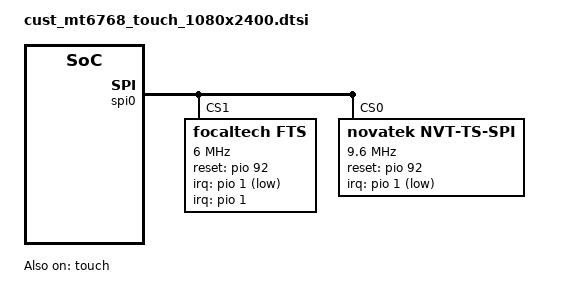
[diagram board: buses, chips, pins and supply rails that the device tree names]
/*
 * Copyright (c) 2019 MediaTek Inc.
 *
 * This program is free software; you can redistribute it and/or modify
 * it under the terms of the GNU General Public License version 2 as
 * published by the Free Software Foundation.
 *
 * This program is distributed in the hope that it will be useful,
 * but WITHOUT ANY WARRANTY; without even the implied warranty of
 * MERCHANTABILITY or FITNESS FOR A PARTICULAR PURPOSE.  See the
 * GNU General Public License for more details.
 */
/* TOUCH start */

&touch {
	tpd-resolution = <1080 2400>;
	use-tpd-button = <0>;
	tpd-key-num = <3>;
	tpd-key-local= <139 172 158 0>;
	tpd-key-dim-local = <90 883 100 40 230
				883 100 40 370 883 100 40 0 0 0 0>;
	tpd-max-touch-num = <10>;
	tpd-filter-enable = <0>;
	tpd-filter-pixel-density = <168>;
	tpd-filter-custom-prameters = <0 0 0 0 0 0 0 0 0 0 0 0>;
	tpd-filter-custom-speed = <0 0 0>;
	pinctrl-names = "default", "state_eint_as_int",
		"state_eint_output0", "state_eint_output1",
		"state_rst_output0", "state_rst_output1";
	pinctrl-0 = <&ctp_pins_default>;
	pinctrl-1 = <&ctp_pins_eint_as_int>;
	pinctrl-2 = <&ctp_pins_eint_output0>;
	pinctrl-3 = <&ctp_pins_eint_output1>;
	pinctrl-4 = <&ctp_pins_rst_output0>;
	pinctrl-5 = <&ctp_pins_rst_output1>;
	status = "okay";
};
&pio {
	ctp_pins_default: eint0default {
	};
	ctp_ts_pins_default: eint1default {
	};
	ctp_pins_eint_as_int: eint@0 {
		pins_cmd_dat {
			pinmux = <PINMUX_GPIO1__FUNC_GPIO1>;
			slew-rate = <0>;
			bias-disable;
		};
	};
	ctp_pins_eint_output0: eintoutput0 {
		pins_cmd_dat {
			pinmux = <PINMUX_GPIO1__FUNC_GPIO1>;
			slew-rate = <1>;
			output-low;
		};
	};
	ctp_pins_eint_output1: eintoutput1 {
		pins_cmd_dat {
			pinmux = <PINMUX_GPIO1__FUNC_GPIO1>;
			slew-rate = <1>;
			output-high;
	};
	};
	ctp_pins_rst_output0: rstoutput0 {
		pins_cmd_dat {
				pinmux = <PINMUX_GPIO92__FUNC_GPIO92>;
				slew-rate = <1>;
				output-low;
			};
	};
	ctp_pins_rst_output1: rstoutput1 {
		pins_cmd_dat {
				pinmux = <PINMUX_GPIO92__FUNC_GPIO92>;
				slew-rate = <1>;
				output-high;
		};
	};

};

&spi0 {
/*K19A coad for HQ-147450 by feiwen at 2021/7/23 start*/
	focaltech@0 {
		compatible = "focaltech,fts";
		reg = <1>;
		status = "ok";
		spi-max-frequency = <6000000>;
		interrupt-parent = <&pio>;
		interrupts = <1 0x2>;
		focaltech,reset-gpio = <&pio 92 0x00>;
		focaltech,irq-gpio = <&pio 1 0x2001>;
		focaltech,max-touch-number = <10>;
		focaltech,display-coords =  <0 0 1080 2400>;
	};
	novatek@0 {
		compatible = "novatek,NVT-ts-spi";
/*K19A coad for HQ-147450 by feiwen at 2021/7/23 end*/
		reg = <0>; //Same as CS ID
		status = "ok";

		spi-max-frequency = <9600000>;	//4800000,9600000,15000000,19200000
		novatek,reset-gpio = <&pio 92 0x00>;
		novatek,irq-gpio = <&pio 1 0x2001>;

		/* 525 */
		//novatek,swrst-n8-addr = <0x01F01A>;

		/* 672A, 525B, 675, 526, 672C */
		novatek,swrst-n8-addr = <0x03F0FE>;
		novatek,spi-rd-fast-addr = <0x03F310>;

		/* MP */
		novatek,mp-support-dt;

		/*for Xiaomi K19A 672C TM6.497" Module*/
		novatek-mp-criteria-5955@0 {
			#address-cells = <1>;
			#size-cells = <0>;
			compatible = "novatek-mp-criteria-5955";

			/* MP Config */
			IC_X_CFG_SIZE = <18>;
			IC_Y_CFG_SIZE = <36>;
			IC_KEY_CFG_SIZE = <4>;
			X_Channel = <18>;
			Y_Channel = <36>;
			AIN_X = <0 1 2 3 4 5 6 7 8 9 10 11 12 13 14 15 16 17>;
			AIN_Y = <0 1 2 3 4 5 6 7 8 9 10 11 12 13 14 15 16 17 18 19 20 21 22 23 24 25 26 27 28 29 30 31 32 33 34 35>;
			//AIN_X = <0 1 2 3 4 5 6 7 8 9 10 11 12 13 14 15 16 17 18 19 20 21 22 23 24 25 26 27 28 29 30 31>;
			//AIN_Y = <0 1 2 3 4 5 6 7 8 9 10 11 12 13 14 15 16 17 18 19 20 21 22 23 24 25 26 27 28 29 30 31 32 33 34 35 36 37 38 39 40 41 42 43 44 45 46 47 48 49>;
			AIN_KEY = <0 1 2 0xFF>;

			/* Huaqin modify for HQ-123586 by shujiawang at 2021/04/16 start */

			/* MP Criteria */
			PS_Config_Lmt_Short_Rawdata_P = <
				14008	14008	14008	14008	14008	14008	14008	14008	14008	14008	14008	14008	14008	14008	14008	14008	14008	14008
				14008	14008	14008	14008	14008	14008	14008	14008	14008	14008	14008	14008	14008	14008	14008	14008	14008	14008
				14008	14008	14008	14008	14008	14008	14008	14008	14008	14008	14008	14008	14008	14008	14008	14008	14008	14008
				14008	14008	14008	14008	14008	14008	14008	14008	14008	14008	14008	14008	14008	14008	14008	14008	14008	14008
				14008	14008	14008	14008	14008	14008	14008	14008	14008	14008	14008	14008	14008	14008	14008	14008	14008	14008
				14008	14008	14008	14008	14008	14008	14008	14008	14008	14008	14008	14008	14008	14008	14008	14008	14008	14008
				14008	14008	14008	14008	14008	14008	14008	14008	14008	14008	14008	14008	14008	14008	14008	14008	14008	14008
				14008	14008	14008	14008	14008	14008	14008	14008	14008	14008	14008	14008	14008	14008	14008	14008	14008	14008
				14008	14008	14008	14008	14008	14008	14008	14008	14008	14008	14008	14008	14008	14008	14008	14008	14008	14008
				14008	14008	14008	14008	14008	14008	14008	14008	14008	14008	14008	14008	14008	14008	14008	14008	14008	14008
				14008	14008	14008	14008	14008	14008	14008	14008	14008	14008	14008	14008	14008	14008	14008	14008	14008	14008
				14008	14008	14008	14008	14008	14008	14008	14008	14008	14008	14008	14008	14008	14008	14008	14008	14008	14008
				14008	14008	14008	14008	14008	14008	14008	14008	14008	14008	14008	14008	14008	14008	14008	14008	14008	14008
				14008	14008	14008	14008	14008	14008	14008	14008	14008	14008	14008	14008	14008	14008	14008	14008	14008	14008
				14008	14008	14008	14008	14008	14008	14008	14008	14008	14008	14008	14008	14008	14008	14008	14008	14008	14008
				14008	14008	14008	14008	14008	14008	14008	14008	14008	14008	14008	14008	14008	14008	14008	14008	14008	14008
				14008	14008	14008	14008	14008	14008	14008	14008	14008	14008	14008	14008	14008	14008	14008	14008	14008	14008
				14008	14008	14008	14008	14008	14008	14008	14008	14008	14008	14008	14008	14008	14008	14008	14008	14008	14008
				14008	14008	14008	14008	14008	14008	14008	14008	14008	14008	14008	14008	14008	14008	14008	14008	14008	14008
				14008	14008	14008	14008	14008	14008	14008	14008	14008	14008	14008	14008	14008	14008	14008	14008	14008	14008
				14008	14008	14008	14008	14008	14008	14008	14008	14008	14008	14008	14008	14008	14008	14008	14008	14008	14008
				14008	14008	14008	14008	14008	14008	14008	14008	14008	14008	14008	14008	14008	14008	14008	14008	14008	14008
				14008	14008	14008	14008	14008	14008	14008	14008	14008	14008	14008	14008	14008	14008	14008	14008	14008	14008
				14008	14008	14008	14008	14008	14008	14008	14008	14008	14008	14008	14008	14008	14008	14008	14008	14008	14008
				14008	14008	14008	14008	14008	14008	14008	14008	14008	14008	14008	14008	14008	14008	14008	14008	14008	14008
				14008	14008	14008	14008	14008	14008	14008	14008	14008	14008	14008	14008	14008	14008	14008	14008	14008	14008
				14008	14008	14008	14008	14008	14008	14008	14008	14008	14008	14008	14008	14008	14008	14008	14008	14008	14008
				14008	14008	14008	14008	14008	14008	14008	14008	14008	14008	14008	14008	14008	14008	14008	14008	14008	14008
				14008	14008	14008	14008	14008	14008	14008	14008	14008	14008	14008	14008	14008	14008	14008	14008	14008	14008
				14008	14008	14008	14008	14008	14008	14008	14008	14008	14008	14008	14008	14008	14008	14008	14008	14008	14008
				14008	14008	14008	14008	14008	14008	14008	14008	14008	14008	14008	14008	14008	14008	14008	14008	14008	14008
				14008	14008	14008	14008	14008	14008	14008	14008	14008	14008	14008	14008	14008	14008	14008	14008	14008	14008
				14008	14008	14008	14008	14008	14008	14008	14008	14008	14008	14008	14008	14008	14008	14008	14008	14008	14008
				14008	14008	14008	14008	14008	14008	14008	14008	14008	14008	14008	14008	14008	14008	14008	14008	14008	14008
				14008	14008	14008	14008	14008	14008	14008	14008	14008	14008	14008	14008	14008	14008	14008	14008	14008	14008
				14008	14008	14008	14008	14008	14008	14008	14008	14008	14008	14008	14008	14008	14008	14008	14008	14008	14008
				14008 14008 14008>;

			PS_Config_Lmt_Short_Rawdata_N = <
				10100	10100	10100	10100	10100	10100	10100	10100	10100	10100	10100	10100	10100	10100	10100	10100	10100	10100
				10100	10100	10100	10100	10100	10100	10100	10100	10100	10100	10100	10100	10100	10100	10100	10100	10100	10100
				10100	10100	10100	10100	10100	10100	10100	10100	10100	10100	10100	10100	10100	10100	10100	10100	10100	10100
				10100	10100	10100	10100	10100	10100	10100	10100	10100	10100	10100	10100	10100	10100	10100	10100	10100	10100
				10100	10100	10100	10100	10100	10100	10100	10100	10100	10100	10100	10100	10100	10100	10100	10100	10100	10100
				10100	10100	10100	10100	10100	10100	10100	10100	10100	10100	10100	10100	10100	10100	10100	10100	10100	10100
				10100	10100	10100	10100	10100	10100	10100	10100	10100	10100	10100	10100	10100	10100	10100	10100	10100	10100
				10100	10100	10100	10100	10100	10100	10100	10100	10100	10100	10100	10100	10100	10100	10100	10100	10100	10100
				10100	10100	10100	10100	10100	10100	10100	10100	10100	10100	10100	10100	10100	10100	10100	10100	10100	10100
				10100	10100	10100	10100	10100	10100	10100	10100	10100	10100	10100	10100	10100	10100	10100	10100	10100	10100
				10100	10100	10100	10100	10100	10100	10100	10100	10100	10100	10100	10100	10100	10100	10100	10100	10100	10100
				10100	10100	10100	10100	10100	10100	10100	10100	10100	10100	10100	10100	10100	10100	10100	10100	10100	10100
				10100	10100	10100	10100	10100	10100	10100	10100	10100	10100	10100	10100	10100	10100	10100	10100	10100	10100
				10100	10100	10100	10100	10100	10100	10100	10100	10100	10100	10100	10100	10100	10100	10100	10100	10100	10100
				10100	10100	10100	10100	10100	10100	10100	10100	10100	10100	10100	10100	10100	10100	10100	10100	10100	10100
				10100	10100	10100	10100	10100	10100	10100	10100	10100	10100	10100	10100	10100	10100	10100	10100	10100	10100
				10100	10100	10100	10100	10100	10100	10100	10100	10100	10100	10100	10100	10100	10100	10100	10100	10100	10100
				10100	10100	10100	10100	10100	10100	10100	10100	10100	10100	10100	10100	10100	10100	10100	10100	10100	10100
				10100	10100	10100	10100	10100	10100	10100	10100	10100	10100	10100	10100	10100	10100	10100	10100	10100	10100
				10100	10100	10100	10100	10100	10100	10100	10100	10100	10100	10100	10100	10100	10100	10100	10100	10100	10100
				10100	10100	10100	10100	10100	10100	10100	10100	10100	10100	10100	10100	10100	10100	10100	10100	10100	10100
				10100	10100	10100	10100	10100	10100	10100	10100	10100	10100	10100	10100	10100	10100	10100	10100	10100	10100
				10100	10100	10100	10100	10100	10100	10100	10100	10100	10100	10100	10100	10100	10100	10100	10100	10100	10100
				10100	10100	10100	10100	10100	10100	10100	10100	10100	10100	10100	10100	10100	10100	10100	10100	10100	10100
				10100	10100	10100	10100	10100	10100	10100	10100	10100	10100	10100	10100	10100	10100	10100	10100	10100	10100
				10100	10100	10100	10100	10100	10100	10100	10100	10100	10100	10100	10100	10100	10100	10100	10100	10100	10100
				10100	10100	10100	10100	10100	10100	10100	10100	10100	10100	10100	10100	10100	10100	10100	10100	10100	10100
				10100	10100	10100	10100	10100	10100	10100	10100	10100	10100	10100	10100	10100	10100	10100	10100	10100	10100
				10100	10100	10100	10100	10100	10100	10100	10100	10100	10100	10100	10100	10100	10100	10100	10100	10100	10100
				10100	10100	10100	10100	10100	10100	10100	10100	10100	10100	10100	10100	10100	10100	10100	10100	10100	10100
				10100	10100	10100	10100	10100	10100	10100	10100	10100	10100	10100	10100	10100	10100	10100	10100	10100	10100
				10100	10100	10100	10100	10100	10100	10100	10100	10100	10100	10100	10100	10100	10100	10100	10100	10100	10100
				10100	10100	10100	10100	10100	10100	10100	10100	10100	10100	10100	10100	10100	10100	10100	10100	10100	10100
				10100	10100	10100	10100	10100	10100	10100	10100	10100	10100	10100	10100	10100	10100	10100	10100	10100	10100
				10100	10100	10100	10100	10100	10100	10100	10100	10100	10100	10100	10100	10100	10100	10100	10100	10100	10100
				10100	10100	10100	10100	10100	10100	10100	10100	10100	10100	10100	10100	10100	10100	10100	10100	10100	10100
				10000 10000 10000>;

			PS_Config_Lmt_Open_Rawdata_P = <
				3207	3206	3302	3382	3417	3455	3509	3547	3544	3593	3595	3543	3455	3395	3336	3239	3105	3043
				3214	3250	3341	3438	3481	3523	3581	3631	3616	3655	3655	3598	3512	3449	3389	3285	3178	3133
				3267	3291	3374	3469	3511	3540	3593	3640	3638	3687	3707	3642	3554	3491	3431	3306	3197	3127
				3269	3309	3411	3519	3563	3593	3644	3689	3726	3750	3680	3628	3550	3491	3427	3294	3182	3151
				3320	3350	3442	3553	3600	3626	3668	3711	3806	3829	3749	3694	3606	3547	3469	3329	3196	3176
				3287	3336	3437	3556	3614	3654	3700	3753	3836	3829	3757	3708	3619	3564	3491	3353	3231	3243
				3378	3403	3498	3600	3654	3686	3731	3780	3885	3893	3819	3767	3689	3626	3546	3414	3267	3260
				3364	3407	3511	3613	3683	3726	3773	3803	3929	3897	3820	3768	3694	3637	3546	3413	3249	3305
				3448	3481	3572	3675	3743	3770	3810	3871	3980	3962	3893	3830	3752	3694	3598	3460	3346	3325
				3423	3472	3570	3679	3761	3798	3850	3920	4012	3967	3897	3843	3764	3712	3612	3477	3371	3386
				3483	3532	3620	3729	3802	3834	3833	3945	4044	4029	3955	3904	3819	3763	3638	3467	3390	3371
				3452	3515	3609	3724	3806	3847	3900	3974	4050	4002	3938	3893	3817	3774	3658	3537	3427	3445
				3533	3581	3675	3778	3868	3899	3950	4012	4102	4044	3984	3935	3862	3799	3680	3568	3455	3434
				3504	3570	3670	3773	3873	3911	3976	4039	4107	4076	4015	3967	3899	3841	3707	3603	3497	3514
				3574	3634	3721	3820	3913	3917	4011	4064	4145	4082	4020	3964	3886	3831	3672	3584	3480	3449
				3558	3638	3729	3830	3936	3988	4051	4116	4174	4103	4044	3987	3915	3859	3739	3621	3529	3536
				3586	3661	3735	3836	3939	4001	4061	4117	4184	4156	4086	4029	3946	3889	3768	3640	3533	3516
				3575	3666	3746	3855	3953	4039	4114	4176	4218	4142	4082	4026	3952	3882	3781	3659	3558	3582
				3684	3616	3647	3704	3724	3792	3861	3920	3981	3988	3956	3906	3829	3754	3735	3680	3628	3596
				3621	3585	3620	3690	3745	3805	3875	3941	4008	4019	3964	3906	3838	3785	3743	3690	3635	3620
				3687	3635	3665	3715	3763	3809	3873	3925	3984	4034	3988	3931	3876	3833	3792	3742	3682	3644
				3649	3623	3663	3693	3782	3836	3913	3964	4025	4022	3952	3899	3822	3815	3777	3725	3668	3651
				3722	3686	3719	3777	3831	3865	3934	3981	4043	4079	4023	3971	3922	3890	3841	3773	3703	3658
				3677	3668	3710	3788	3850	3900	3980	4033	4093	4057	3987	3931	3892	3861	3819	3756	3693	3668
				3715	3687	3733	3799	3854	3896	3960	4004	4057	4088	4030	3980	3939	3901	3857	3794	3719	3680
				3684	3690	3712	3802	3859	3908	3974	4029	4095	4124	4044	3963	3949	3914	3875	3810	3739	3715
				3756	3733	3791	3851	3908	3945	4011	4050	4109	4089	4023	3971	3936	3896	3859	3795	3731	3684
				3693	3698	3771	3836	3899	3941	4013	4057	4121	4145	4058	4013	3974	3939	3897	3834	3771	3743
				3749	3721	3806	3873	3922	3960	4025	4065	4132	4111	4026	4004	3960	3928	3883	3816	3745	3690
				3684	3705	3778	3854	3904	3950	4027	4069	4138	4118	4047	4009	3970	3943	3907	3845	3775	3749
				3746	3745	3822	3889	3934	3970	4033	4068	4125	4106	4050	4011	3971	3932	3892	3834	3752	3704
				3679	3707	3792	3857	3908	3964	4033	4081	4153	4142	4074	4039	4001	3971	3935	3871	3780	3763
				3728	3759	3841	3894	3939	3974	4034	4065	4128	4121	4085	4047	4011	3976	3942	3879	3788	3743
				3686	3833	3945	4012	4065	4113	4193	4240	4307	4249	4184	4144	4097	4060	4013	3939	3837	3712
				3536	3844	3948	4016	4071	4116	4187	4230	4300	4233	4174	4135	4074	4039	3990	3922	3802	3509
				3323	3760	3925	4008	4062	4107	4180	4233	4307	4260	4202	4174	4120	4089	4050	3978	3812	3421
				5120 5120 5120>;

			PS_Config_Lmt_Open_Rawdata_N = <
				1374	1374	1415	1449	1464	1480	1504	1520	1519	1540	1540	1518	1480	1455	1429	1388	1330	1304
				1377	1393	1432	1473	1492	1510	1534	1556	1549	1566	1566	1542	1505	1478	1452	1408	1362	1342
				1400	1410	1446	1486	1504	1517	1540	1560	1559	1580	1588	1561	1523	1496	1470	1417	1370	1340
				1401	1418	1462	1508	1527	1540	1561	1581	1597	1607	1577	1555	1521	1496	1468	1411	1363	1350
				1423	1435	1475	1522	1543	1554	1572	1590	1631	1641	1606	1583	1545	1520	1486	1426	1369	1361
				1408	1429	1473	1524	1549	1566	1585	1608	1644	1641	1610	1589	1551	1527	1496	1437	1384	1390
				1447	1458	1499	1543	1566	1579	1599	1620	1665	1668	1636	1614	1581	1554	1519	1463	1400	1397
				1441	1460	1504	1548	1578	1597	1617	1630	1684	1670	1637	1615	1583	1558	1519	1462	1392	1416
				1477	1492	1531	1575	1604	1615	1633	1659	1705	1698	1668	1641	1608	1583	1542	1483	1434	1425
				1467	1488	1530	1576	1612	1627	1650	1680	1719	1700	1670	1647	1613	1591	1548	1490	1444	1451
				1492	1513	1551	1598	1629	1643	1642	1690	1733	1726	1695	1673	1636	1612	1559	1486	1453	1444
				1479	1506	1546	1596	1631	1648	1671	1703	1735	1715	1687	1668	1636	1617	1567	1516	1468	1476
				1514	1534	1575	1619	1657	1671	1693	1719	1758	1733	1707	1686	1655	1628	1577	1529	1480	1471
				1501	1530	1573	1617	1660	1676	1704	1731	1760	1747	1720	1700	1671	1646	1588	1544	1498	1506
				1531	1557	1594	1637	1677	1678	1719	1741	1776	1749	1723	1699	1665	1642	1573	1536	1491	1478
				1525	1559	1598	1641	1687	1709	1736	1764	1789	1758	1733	1708	1678	1654	1602	1552	1512	1515
				1537	1569	1600	1644	1688	1714	1740	1764	1793	1781	1751	1726	1691	1666	1615	1560	1514	1507
				1532	1571	1605	1652	1694	1731	1763	1789	1807	1775	1749	1725	1693	1663	1620	1568	1525	1535
				1579	1549	1563	1587	1596	1625	1654	1680	1706	1709	1695	1674	1641	1609	1600	1577	1555	1541
				1552	1536	1551	1581	1605	1630	1660	1689	1717	1722	1699	1674	1645	1622	1604	1581	1558	1551
				1580	1558	1570	1592	1612	1632	1660	1682	1707	1729	1709	1684	1661	1642	1625	1603	1578	1561
				1564	1552	1570	1582	1621	1644	1677	1699	1725	1723	1693	1671	1638	1635	1618	1596	1572	1564
				1595	1579	1594	1618	1642	1656	1686	1706	1732	1748	1724	1702	1681	1667	1646	1617	1587	1567
				1576	1572	1590	1623	1650	1671	1705	1728	1754	1738	1708	1684	1668	1654	1636	1609	1582	1572
				1592	1580	1600	1628	1651	1669	1697	1716	1738	1752	1727	1705	1688	1672	1653	1626	1594	1577
				1579	1581	1591	1629	1654	1675	1703	1726	1755	1767	1733	1698	1692	1677	1660	1633	1602	1592
				1609	1600	1624	1650	1675	1690	1719	1735	1761	1752	1724	1702	1687	1669	1654	1626	1599	1579
				1582	1585	1616	1644	1671	1689	1720	1738	1766	1776	1739	1720	1703	1688	1670	1643	1616	1604
				1606	1594	1631	1660	1681	1697	1725	1742	1771	1762	1725	1716	1697	1683	1664	1635	1605	1581
				1579	1588	1619	1651	1673	1693	1726	1744	1773	1765	1734	1718	1701	1690	1674	1648	1618	1606
				1605	1605	1638	1666	1686	1701	1728	1743	1768	1759	1735	1719	1702	1685	1668	1643	1608	1587
				1576	1588	1625	1653	1675	1699	1728	1749	1780	1775	1746	1731	1714	1702	1686	1659	1620	1612
				1597	1611	1646	1669	1688	1703	1729	1742	1769	1766	1750	1734	1719	1704	1689	1662	1623	1604
				1579	1642	1690	1719	1742	1762	1797	1817	1846	1821	1793	1776	1756	1740	1720	1688	1644	1591
				1515	1647	1692	1721	1744	1764	1794	1813	1843	1814	1789	1772	1746	1731	1710	1681	1629	1504
				1424	1611	1682	1717	1741	1760	1791	1814	1846	1825	1801	1789	1765	1752	1735	1705	1633	1466
				(-511) (-511) (-511)>;

			PS_Config_Lmt_FW_Rawdata_P = <
				1129	1118	1120	1108	1108	1108	1108	1104	1122	1120	1114	1106	1110	1101	1111	1108	1122	1115
				1096	1121	1124	1097	1115	1097	1094	1117	1117	1129	1125	1113	1115	1114	1108	1108	1113	1125
				1111	1117	1117	1107	1122	1108	1108	1108	1129	1111	1115	1110	1104	1108	1113	1115	1118	1106
				1108	1110	1110	1115	1118	1118	1111	1107	1121	1118	1110	1113	1117	1115	1114	1110	1121	1117
				1104	1117	1110	1106	1111	1097	1099	1097	1107	1117	1120	1121	1121	1111	1118	1122	1120	1103
				1108	1125	1125	1108	1132	1097	1101	1100	1113	1125	1131	1125	1128	1134	1134	1131	1135	1096
				1108	1121	1121	1110	1120	1106	1108	1106	1113	1118	1113	1107	1113	1114	1113	1110	1101	1114
				1093	1132	1120	1113	1125	1096	1103	1108	1118	1121	1115	1115	1113	1106	1104	1113	1108	1114
				1114	1122	1111	1113	1117	1117	1115	1117	1117	1111	1107	1100	1104	1120	1113	1125	1117	1107
				1114	1121	1128	1121	1122	1107	1111	1110	1120	1120	1111	1114	1121	1115	1115	1122	1111	1106
				1100	1135	1132	1110	1122	1090	1093	1096	1099	1132	1128	1121	1100	1100	1100	1092	1090	1120
				1127	1106	1113	1118	1114	1132	1135	1114	1117	1113	1121	1121	1124	1120	1120	1120	1118	1101
				1113	1122	1122	1124	1125	1120	1117	1101	1124	1111	1113	1114	1114	1108	1111	1121	1120	1115
				1107	1125	1107	1096	1100	1097	1103	1129	1107	1122	1106	1108	1113	1117	1120	1118	1115	1106
				1108	1121	1122	1108	1121	1114	1114	1114	1124	1097	1106	1107	1124	1125	1127	1113	1117	1111
				1107	1125	1117	1113	1117	1103	1104	1122	1114	1121	1121	1122	1114	1117	1113	1113	1108	1110
				1113	1122	1128	1115	1120	1111	1108	1108	1115	1114	1110	1114	1113	1113	1104	1114	1115	1118
				1122	1108	1113	1117	1122	1122	1118	1120	1103	1125	1103	1115	1118	1104	1104	1103	1106	1113
				1113	1103	1107	1103	1103	1128	1120	1113	1122	1114	1118	1111	1107	1103	1101	1113	1127	1108
				1115	1113	1106	1104	1097	1115	1114	1106	1128	1114	1115	1107	1103	1111	1111	1120	1121	1107
				1115	1114	1113	1111	1113	1113	1115	1118	1120	1136	1111	1094	1092	1132	1103	1129	1132	1101
				1107	1108	1110	1115	1114	1115	1142	1138	1103	1113	1128	1100	1097	1108	1099	1106	1103	1118
				1117	1101	1087	1094	1092	1093	1111	1110	1121	1107	1115	1131	1129	1120	1121	1120	1104	1118
				1117	1124	1115	1114	1115	1113	1127	1122	1113	1114	1114	1111	1108	1120	1115	1115	1118	1121
				1118	1128	1127	1117	1127	1122	1127	1127	1125	1128	1121	1110	1111	1104	1097	1096	1110	1115
				1120	1104	1100	1104	1107	1103	1108	1110	1121	1129	1122	1093	1103	1101	1103	1101	1101	1114
				1118	1110	1111	1111	1111	1110	1121	1114	1124	1111	1121	1124	1122	1129	1132	1134	1129	1111
				1115	1111	1101	1103	1099	1101	1107	1114	1128	1129	1118	1101	1100	1103	1103	1100	1106	1121
				1103	1117	1121	1118	1120	1120	1118	1121	1115	1110	1127	1128	1124	1124	1125	1124	1124	1103
				1118	1103	1108	1104	1111	1108	1107	1108	1127	1114	1115	1125	1127	1125	1131	1127	1131	1110
				1117	1107	1117	1108	1120	1110	1115	1118	1118	1111	1120	1104	1121	1128	1125	1120	1121	1124
				1099	1122	1121	1124	1122	1111	1117	1117	1101	1120	1113	1125	1134	1124	1124	1124	1120	1113
				1120	1118	1111	1124	1114	1127	1108	1121	1120	1135	1132	1135	1127	1121	1124	1132	1110	1100
				1122	1120	1101	1108	1104	1110	1101	1110	1121	1115	1106	1120	1118	1124	1121	1129	1115	1108
				1121	1115	1117	1114	1121	1120	1125	1121	1110	1128	1118	1128	1117	1118	1115	1122	1114	1121
				1113	1121	1115	1114	1108	1111	1115	1122	1111	1103	1113	1127	1124	1127	1100	1114	1096	1092
				2560 2560 2560>;

			PS_Config_Lmt_FW_Rawdata_N = <
				484	479	480	475	475	475	475	473	481	480	477	474	475	472	476	475	481	478
				469	480	481	470	478	470	469	478	478	484	482	477	478	477	475	475	477	482
				476	478	478	474	481	475	475	475	484	476	478	475	473	475	477	478	479	474
				475	475	475	478	479	479	476	474	480	479	475	477	478	478	477	475	480	478
				473	478	475	474	476	470	471	470	474	478	480	480	480	476	479	481	480	472
				475	482	482	475	485	470	472	471	477	482	484	482	483	486	486	484	486	469
				475	480	480	475	480	474	475	474	477	479	477	474	477	477	477	475	472	477
				468	485	480	477	482	469	472	475	479	480	478	478	477	474	473	477	475	477
				477	481	476	477	478	478	478	478	478	476	474	471	473	480	477	482	478	474
				477	480	483	480	481	474	476	475	480	480	476	477	480	478	478	481	476	474
				471	486	485	475	481	467	468	469	471	485	483	480	471	471	471	468	467	480
				483	474	477	479	477	485	486	477	478	477	480	480	481	480	480	480	479	472
				477	481	481	481	482	480	478	472	481	476	477	477	477	475	476	480	480	478
				474	482	474	469	471	470	472	484	474	481	474	475	477	478	480	479	478	474
				475	480	481	475	480	477	477	477	481	470	474	474	481	482	483	477	478	476
				474	482	478	477	478	472	473	481	477	480	480	481	477	478	477	477	475	475
				477	481	483	478	480	476	475	475	478	477	475	477	477	477	473	477	478	479
				481	475	477	478	481	481	479	480	472	482	472	478	479	473	473	472	474	477
				477	472	474	472	472	483	480	477	481	477	479	476	474	472	472	477	483	475
				478	477	474	473	470	478	477	474	483	477	478	474	472	476	476	480	480	474
				478	477	477	476	477	477	478	479	480	487	476	469	468	485	472	484	485	472
				474	475	475	478	477	478	489	487	472	477	483	471	470	475	471	474	472	479
				478	472	466	469	468	468	476	475	480	474	478	484	484	480	480	480	473	479
				478	481	478	477	478	477	483	481	477	477	477	476	475	480	478	478	479	480
				479	483	483	478	483	481	483	483	482	483	480	475	476	473	470	469	475	478
				480	473	471	473	474	472	475	475	480	484	481	468	472	472	472	472	472	477
				479	475	476	476	476	475	480	477	481	476	480	481	481	484	485	486	484	476
				478	476	472	472	471	472	474	477	483	484	479	472	471	472	472	471	474	480
				472	478	480	479	480	480	479	480	478	475	483	483	481	481	482	481	481	472
				479	472	475	473	476	475	474	475	483	477	478	482	483	482	484	483	484	475
				478	474	478	475	480	475	478	479	479	476	480	473	480	483	482	480	480	481
				471	481	480	481	481	476	478	478	472	480	477	482	486	481	481	481	480	477
				480	479	476	481	477	483	475	480	480	486	485	486	483	480	481	485	475	471
				481	480	472	475	473	475	472	475	480	478	474	480	479	481	480	484	478	475
				480	478	478	477	480	480	482	480	475	483	479	483	478	479	478	481	477	480
				477	480	478	477	475	476	478	481	476	472	477	483	481	483	471	477	469	468
				240 240 240>;

			PS_Config_Lmt_FW_CC_P = <
				52	52	52	53	52	53	53	53	55	55	53	53	53	52	52	52	52	52
				52	52	52	52	52	52	52	53	55	53	52	52	52	52	52	52	52	52
				52	52	52	52	52	52	52	52	55	53	52	52	52	52	52	52	52	52
				53	52	52	52	52	52	52	53	55	53	52	52	52	52	52	52	52	53
				52	52	52	52	52	52	52	52	53	53	52	52	52	52	52	52	52	52
				53	52	52	52	52	53	53	53	55	53	52	52	52	52	52	52	52	53
				52	52	52	52	52	52	52	52	53	53	52	52	52	52	52	52	52	52
				53	52	52	52	52	53	53	53	55	55	53	53	52	52	52	52	52	53
				52	52	52	52	52	52	52	52	53	55	53	53	52	52	52	52	52	53
				53	52	52	52	52	53	53	53	55	55	53	52	52	52	52	52	52	53
				52	52	52	52	52	52	52	53	55	55	53	53	52	52	53	52	52	53
				53	52	52	53	53	53	53	53	55	55	53	53	52	52	52	52	52	53
				52	52	52	52	52	52	52	53	55	53	53	53	52	52	52	52	52	53
				53	52	52	53	52	53	53	53	55	53	53	53	52	52	52	52	52	53
				52	52	52	52	52	52	53	53	55	53	53	53	52	52	52	52	52	53
				53	52	52	53	52	53	53	53	56	53	52	52	52	52	52	52	52	53
				52	52	52	52	52	52	53	53	55	53	53	53	53	52	52	52	52	53
				53	52	52	52	52	53	53	53	56	53	52	52	52	52	52	52	52	53
				53	52	52	52	52	52	52	52	52	56	53	53	52	52	52	52	52	53
				53	52	52	52	52	53	53	53	53	56	53	53	53	52	52	52	52	53
				52	52	52	52	52	52	52	52	52	55	53	53	53	52	52	52	52	53
				53	52	52	52	52	52	53	53	53	55	53	53	53	52	52	52	52	53
				53	52	52	52	52	52	52	52	53	55	53	53	53	52	52	52	52	53
				53	52	52	52	52	52	53	53	53	55	53	52	53	52	52	52	52	53
				53	52	52	52	52	52	52	52	53	55	53	53	53	52	53	52	52	53
				53	53	53	53	53	53	53	53	55	55	53	53	53	52	52	52	52	53
				53	52	52	52	52	52	52	52	55	55	52	52	52	52	52	52	52	53
				53	52	53	53	53	53	53	53	55	55	53	53	53	53	53	53	52	53
				53	52	52	52	52	52	52	52	53	55	53	53	53	52	52	52	52	53
				53	52	52	52	52	52	53	53	55	55	53	52	52	52	52	52	52	53
				53	52	52	52	52	52	52	52	53	55	52	53	52	52	52	52	52	53
				53	52	53	52	53	52	53	52	55	55	53	53	53	52	53	53	52	53
				53	52	52	52	53	52	52	52	55	55	52	52	52	52	52	52	52	53
				53	53	53	53	53	53	53	53	56	55	53	52	52	52	52	52	52	53
				52	52	52	52	52	52	52	52	55	55	52	52	52	52	52	52	52	52
				52	52	53	53	53	53	53	53	56	55	53	53	52	52	52	52	52	52
				314 314 314>;

			PS_Config_Lmt_FW_CC_N = <
				23	23	23	24	23	24	24	24	24	24	24	24	24	23	23	23	23	23
				23	23	23	23	23	23	23	24	24	24	23	23	23	23	23	23	23	23
				23	23	23	23	23	23	23	23	24	24	23	23	23	23	23	23	23	23
				24	23	23	23	23	23	23	24	24	24	23	23	23	23	23	23	23	24
				23	23	23	23	23	23	23	23	24	24	23	23	23	23	23	23	23	23
				24	23	23	23	23	24	24	24	24	24	23	23	23	23	23	23	23	24
				23	23	23	23	23	23	23	23	24	24	23	23	23	23	23	23	23	23
				24	23	23	23	23	24	24	24	24	24	24	24	23	23	23	23	23	24
				23	23	23	23	23	23	23	23	24	24	24	24	23	23	23	23	23	24
				24	23	23	23	23	24	24	24	24	24	24	23	23	23	23	23	23	24
				23	23	23	23	23	23	23	24	24	24	24	24	23	23	24	23	23	24
				24	23	23	24	24	24	24	24	24	24	24	24	23	23	23	23	23	24
				23	23	23	23	23	23	23	24	24	24	24	24	23	23	23	23	23	24
				24	23	23	24	23	24	24	24	24	24	24	24	23	23	23	23	23	24
				23	23	23	23	23	23	24	24	24	24	24	24	23	23	23	23	23	24
				24	23	23	24	23	24	24	24	25	24	23	23	23	23	23	23	23	24
				23	23	23	23	23	23	24	24	24	24	24	24	24	23	23	23	23	24
				24	23	23	23	23	24	24	24	25	24	23	23	23	23	23	23	23	24
				24	23	23	23	23	23	23	23	23	25	24	24	23	23	23	23	23	24
				24	23	23	23	23	24	24	24	24	25	24	24	24	23	23	23	23	24
				23	23	23	23	23	23	23	23	23	24	24	24	24	23	23	23	23	24
				24	23	23	23	23	23	24	24	24	24	24	24	24	23	23	23	23	24
				24	23	23	23	23	23	23	23	24	24	24	24	24	23	23	23	23	24
				24	23	23	23	23	23	24	24	24	24	24	23	24	23	23	23	23	24
				24	23	23	23	23	23	23	23	24	24	24	24	24	23	24	23	23	24
				24	24	24	24	24	24	24	24	24	24	24	24	24	23	23	23	23	24
				24	23	23	23	23	23	23	23	24	24	23	23	23	23	23	23	23	24
				24	23	24	24	24	24	24	24	24	24	24	24	24	24	24	24	23	24
				24	23	23	23	23	23	23	23	24	24	24	24	24	23	23	23	23	24
				24	23	23	23	23	23	24	24	24	24	24	23	23	23	23	23	23	24
				24	23	23	23	23	23	23	23	24	24	23	24	23	23	23	23	23	24
				24	23	24	23	24	23	24	23	24	24	24	24	24	23	24	24	23	24
				24	23	23	23	24	23	23	23	24	24	23	23	23	23	23	23	23	24
				24	24	24	24	24	24	24	24	25	24	24	23	23	23	23	23	23	24
				23	23	23	23	23	23	23	23	24	24	23	23	23	23	23	23	23	23
				23	23	24	24	24	24	24	24	25	24	24	24	23	23	23	23	23	23
				0 0 0>;

			PS_Config_Lmt_FW_Diff_P = <
				50	50	50	50	50	50	50	50	50	50	50	50	50	50	50	50	50	50
				50	50	50	50	50	50	50	50	50	50	50	50	50	50	50	50	50	50
				50	50	50	50	50	50	50	50	50	50	50	50	50	50	50	50	50	50
				50	50	50	50	50	50	50	50	50	50	50	50	50	50	50	50	50	50
				50	50	50	50	50	50	50	50	50	50	50	50	50	50	50	50	50	50
				50	50	50	50	50	50	50	50	50	50	50	50	50	50	50	50	50	50
				50	50	50	50	50	50	50	50	50	50	50	50	50	50	50	50	50	50
				50	50	50	50	50	50	50	50	50	50	50	50	50	50	50	50	50	50
				50	50	50	50	50	50	50	50	50	50	50	50	50	50	50	50	50	50
				50	50	50	50	50	50	50	50	50	50	50	50	50	50	50	50	50	50
				50	50	50	50	50	50	50	50	50	50	50	50	50	50	50	50	50	50
				50	50	50	50	50	50	50	50	50	50	50	50	50	50	50	50	50	50
				50	50	50	50	50	50	50	50	50	50	50	50	50	50	50	50	50	50
				50	50	50	50	50	50	50	50	50	50	50	50	50	50	50	50	50	50
				50	50	50	50	50	50	50	50	50	50	50	50	50	50	50	50	50	50
				50	50	50	50	50	50	50	50	50	50	50	50	50	50	50	50	50	50
				50	50	50	50	50	50	50	50	50	50	50	50	50	50	50	50	50	50
				50	50	50	50	50	50	50	50	50	50	50	50	50	50	50	50	50	50
				50	50	50	50	50	50	50	50	50	50	50	50	50	50	50	50	50	50
				50	50	50	50	50	50	50	50	50	50	50	50	50	50	50	50	50	50
				50	50	50	50	50	50	50	50	50	50	50	50	50	50	50	50	50	50
				50	50	50	50	50	50	50	50	50	50	50	50	50	50	50	50	50	50
				50	50	50	50	50	50	50	50	50	50	50	50	50	50	50	50	50	50
				50	50	50	50	50	50	50	50	50	50	50	50	50	50	50	50	50	50
				50	50	50	50	50	50	50	50	50	50	50	50	50	50	50	50	50	50
				50	50	50	50	50	50	50	50	50	50	50	50	50	50	50	50	50	50
				50	50	50	50	50	50	50	50	50	50	50	50	50	50	50	50	50	50
				50	50	50	50	50	50	50	50	50	50	50	50	50	50	50	50	50	50
				50	50	50	50	50	50	50	50	50	50	50	50	50	50	50	50	50	50
				50	50	50	50	50	50	50	50	50	50	50	50	50	50	50	50	50	50
				50	50	50	50	50	50	50	50	50	50	50	50	50	50	50	50	50	50
				50	50	50	50	50	50	50	50	50	50	50	50	50	50	50	50	50	50
				50	50	50	50	50	50	50	50	50	50	50	50	50	50	50	50	50	50
				50	50	50	50	50	50	50	50	50	50	50	50	50	50	50	50	50	50
				50	50	50	50	50	50	50	50	50	50	50	50	50	50	50	50	50	50
				50	50	50	50	50	50	50	50	50	50	50	50	50	50	50	50	50	50
				75 75 75>;

			PS_Config_Lmt_FW_Diff_N = <
				(-50)	(-50)	(-50)	(-50)	(-50)	(-50)	(-50)	(-50)	(-50)	(-50)	(-50)	(-50)	(-50)	(-50)	(-50)	(-50)	(-50)	(-50)
				(-50)	(-50)	(-50)	(-50)	(-50)	(-50)	(-50)	(-50)	(-50)	(-50)	(-50)	(-50)	(-50)	(-50)	(-50)	(-50)	(-50)	(-50)
				(-50)	(-50)	(-50)	(-50)	(-50)	(-50)	(-50)	(-50)	(-50)	(-50)	(-50)	(-50)	(-50)	(-50)	(-50)	(-50)	(-50)	(-50)
				(-50)	(-50)	(-50)	(-50)	(-50)	(-50)	(-50)	(-50)	(-50)	(-50)	(-50)	(-50)	(-50)	(-50)	(-50)	(-50)	(-50)	(-50)
				(-50)	(-50)	(-50)	(-50)	(-50)	(-50)	(-50)	(-50)	(-50)	(-50)	(-50)	(-50)	(-50)	(-50)	(-50)	(-50)	(-50)	(-50)
				(-50)	(-50)	(-50)	(-50)	(-50)	(-50)	(-50)	(-50)	(-50)	(-50)	(-50)	(-50)	(-50)	(-50)	(-50)	(-50)	(-50)	(-50)
				(-50)	(-50)	(-50)	(-50)	(-50)	(-50)	(-50)	(-50)	(-50)	(-50)	(-50)	(-50)	(-50)	(-50)	(-50)	(-50)	(-50)	(-50)
				(-50)	(-50)	(-50)	(-50)	(-50)	(-50)	(-50)	(-50)	(-50)	(-50)	(-50)	(-50)	(-50)	(-50)	(-50)	(-50)	(-50)	(-50)
				(-50)	(-50)	(-50)	(-50)	(-50)	(-50)	(-50)	(-50)	(-50)	(-50)	(-50)	(-50)	(-50)	(-50)	(-50)	(-50)	(-50)	(-50)
				(-50)	(-50)	(-50)	(-50)	(-50)	(-50)	(-50)	(-50)	(-50)	(-50)	(-50)	(-50)	(-50)	(-50)	(-50)	(-50)	(-50)	(-50)
				(-50)	(-50)	(-50)	(-50)	(-50)	(-50)	(-50)	(-50)	(-50)	(-50)	(-50)	(-50)	(-50)	(-50)	(-50)	(-50)	(-50)	(-50)
				(-50)	(-50)	(-50)	(-50)	(-50)	(-50)	(-50)	(-50)	(-50)	(-50)	(-50)	(-50)	(-50)	(-50)	(-50)	(-50)	(-50)	(-50)
				(-50)	(-50)	(-50)	(-50)	(-50)	(-50)	(-50)	(-50)	(-50)	(-50)	(-50)	(-50)	(-50)	(-50)	(-50)	(-50)	(-50)	(-50)
				(-50)	(-50)	(-50)	(-50)	(-50)	(-50)	(-50)	(-50)	(-50)	(-50)	(-50)	(-50)	(-50)	(-50)	(-50)	(-50)	(-50)	(-50)
				(-50)	(-50)	(-50)	(-50)	(-50)	(-50)	(-50)	(-50)	(-50)	(-50)	(-50)	(-50)	(-50)	(-50)	(-50)	(-50)	(-50)	(-50)
				(-50)	(-50)	(-50)	(-50)	(-50)	(-50)	(-50)	(-50)	(-50)	(-50)	(-50)	(-50)	(-50)	(-50)	(-50)	(-50)	(-50)	(-50)
				(-50)	(-50)	(-50)	(-50)	(-50)	(-50)	(-50)	(-50)	(-50)	(-50)	(-50)	(-50)	(-50)	(-50)	(-50)	(-50)	(-50)	(-50)
				(-50)	(-50)	(-50)	(-50)	(-50)	(-50)	(-50)	(-50)	(-50)	(-50)	(-50)	(-50)	(-50)	(-50)	(-50)	(-50)	(-50)	(-50)
				(-50)	(-50)	(-50)	(-50)	(-50)	(-50)	(-50)	(-50)	(-50)	(-50)	(-50)	(-50)	(-50)	(-50)	(-50)	(-50)	(-50)	(-50)
				(-50)	(-50)	(-50)	(-50)	(-50)	(-50)	(-50)	(-50)	(-50)	(-50)	(-50)	(-50)	(-50)	(-50)	(-50)	(-50)	(-50)	(-50)
				(-50)	(-50)	(-50)	(-50)	(-50)	(-50)	(-50)	(-50)	(-50)	(-50)	(-50)	(-50)	(-50)	(-50)	(-50)	(-50)	(-50)	(-50)
				(-50)	(-50)	(-50)	(-50)	(-50)	(-50)	(-50)	(-50)	(-50)	(-50)	(-50)	(-50)	(-50)	(-50)	(-50)	(-50)	(-50)	(-50)
				(-50)	(-50)	(-50)	(-50)	(-50)	(-50)	(-50)	(-50)	(-50)	(-50)	(-50)	(-50)	(-50)	(-50)	(-50)	(-50)	(-50)	(-50)
				(-50)	(-50)	(-50)	(-50)	(-50)	(-50)	(-50)	(-50)	(-50)	(-50)	(-50)	(-50)	(-50)	(-50)	(-50)	(-50)	(-50)	(-50)
				(-50)	(-50)	(-50)	(-50)	(-50)	(-50)	(-50)	(-50)	(-50)	(-50)	(-50)	(-50)	(-50)	(-50)	(-50)	(-50)	(-50)	(-50)
				(-50)	(-50)	(-50)	(-50)	(-50)	(-50)	(-50)	(-50)	(-50)	(-50)	(-50)	(-50)	(-50)	(-50)	(-50)	(-50)	(-50)	(-50)
				(-50)	(-50)	(-50)	(-50)	(-50)	(-50)	(-50)	(-50)	(-50)	(-50)	(-50)	(-50)	(-50)	(-50)	(-50)	(-50)	(-50)	(-50)
				(-50)	(-50)	(-50)	(-50)	(-50)	(-50)	(-50)	(-50)	(-50)	(-50)	(-50)	(-50)	(-50)	(-50)	(-50)	(-50)	(-50)	(-50)
				(-50)	(-50)	(-50)	(-50)	(-50)	(-50)	(-50)	(-50)	(-50)	(-50)	(-50)	(-50)	(-50)	(-50)	(-50)	(-50)	(-50)	(-50)
				(-50)	(-50)	(-50)	(-50)	(-50)	(-50)	(-50)	(-50)	(-50)	(-50)	(-50)	(-50)	(-50)	(-50)	(-50)	(-50)	(-50)	(-50)
				(-50)	(-50)	(-50)	(-50)	(-50)	(-50)	(-50)	(-50)	(-50)	(-50)	(-50)	(-50)	(-50)	(-50)	(-50)	(-50)	(-50)	(-50)
				(-50)	(-50)	(-50)	(-50)	(-50)	(-50)	(-50)	(-50)	(-50)	(-50)	(-50)	(-50)	(-50)	(-50)	(-50)	(-50)	(-50)	(-50)
				(-50)	(-50)	(-50)	(-50)	(-50)	(-50)	(-50)	(-50)	(-50)	(-50)	(-50)	(-50)	(-50)	(-50)	(-50)	(-50)	(-50)	(-50)
				(-50)	(-50)	(-50)	(-50)	(-50)	(-50)	(-50)	(-50)	(-50)	(-50)	(-50)	(-50)	(-50)	(-50)	(-50)	(-50)	(-50)	(-50)
				(-50)	(-50)	(-50)	(-50)	(-50)	(-50)	(-50)	(-50)	(-50)	(-50)	(-50)	(-50)	(-50)	(-50)	(-50)	(-50)	(-50)	(-50)
				(-50)	(-50)	(-50)	(-50)	(-50)	(-50)	(-50)	(-50)	(-50)	(-50)	(-50)	(-50)	(-50)	(-50)	(-50)	(-50)	(-50)	(-50)
				(-75) (-75) (-75)>;

			PS_Config_Lmt_PenTipX_FW_Raw_P = <
				570 570 570 570 570 570 570 570 570 570 570 570 570 570 570 570 570 570 570 570 570 570 570 570 570 570 570 570 570 570 570 570
				570 570 570 570 570 570 570 570 570 570 570 570 570 570 570 570 570 570 570 570 570 570 570 570 570 570 570 570 570 570 570 570
				570 570 570 570 570 570 570 570 570 570 570 570 570 570 570 570 570 570 570 570 570 570 570 570 570 570 570 570 570 570 570 570
				570 570 570 570 570 570 570 570 570 570 570 570 570 570 570 570 570 570 570 570 570 570 570 570 570 570 570 570 570 570 570 570
				570 570 570 570 570 570 570 570 570 570 570 570 570 570 570 570 570 570 570 570 570 570 570 570 570 570 570 570 570 570 570 570
				570 570 570 570 570 570 570 570 570 570 570 570 570 570 570 570 570 570 570 570 570 570 570 570 570 570 570 570 570 570 570 570>;

			PS_Config_Lmt_PenTipX_FW_Raw_N = <
				(-570) (-570) (-570) (-570) (-570) (-570) (-570) (-570) (-570) (-570) (-570) (-570) (-570) (-570) (-570) (-570) (-570) (-570) (-570) (-570) (-570) (-570) (-570) (-570) (-570) (-570) (-570) (-570) (-570) (-570) (-570) (-570)
				(-570) (-570) (-570) (-570) (-570) (-570) (-570) (-570) (-570) (-570) (-570) (-570) (-570) (-570) (-570) (-570) (-570) (-570) (-570) (-570) (-570) (-570) (-570) (-570) (-570) (-570) (-570) (-570) (-570) (-570) (-570) (-570)
				(-570) (-570) (-570) (-570) (-570) (-570) (-570) (-570) (-570) (-570) (-570) (-570) (-570) (-570) (-570) (-570) (-570) (-570) (-570) (-570) (-570) (-570) (-570) (-570) (-570) (-570) (-570) (-570) (-570) (-570) (-570) (-570)
				(-570) (-570) (-570) (-570) (-570) (-570) (-570) (-570) (-570) (-570) (-570) (-570) (-570) (-570) (-570) (-570) (-570) (-570) (-570) (-570) (-570) (-570) (-570) (-570) (-570) (-570) (-570) (-570) (-570) (-570) (-570) (-570)
				(-570) (-570) (-570) (-570) (-570) (-570) (-570) (-570) (-570) (-570) (-570) (-570) (-570) (-570) (-570) (-570) (-570) (-570) (-570) (-570) (-570) (-570) (-570) (-570) (-570) (-570) (-570) (-570) (-570) (-570) (-570) (-570)
				(-570) (-570) (-570) (-570) (-570) (-570) (-570) (-570) (-570) (-570) (-570) (-570) (-570) (-570) (-570) (-570) (-570) (-570) (-570) (-570) (-570) (-570) (-570) (-570) (-570) (-570) (-570) (-570) (-570) (-570) (-570) (-570)>;

			PS_Config_Lmt_PenTipY_FW_Raw_P = <
				570 570 570 570
				570 570 570 570
				570 570 570 570
				570 570 570 570
				570 570 570 570
				570 570 570 570
				570 570 570 570
				570 570 570 570
				570 570 570 570
				570 570 570 570
				570 570 570 570
				570 570 570 570
				570 570 570 570
				570 570 570 570
				570 570 570 570
				570 570 570 570
				570 570 570 570
				570 570 570 570
				570 570 570 570
				570 570 570 570
				570 570 570 570
				570 570 570 570
				570 570 570 570
				570 570 570 570
				570 570 570 570
				570 570 570 570
				570 570 570 570
				570 570 570 570
				570 570 570 570
				570 570 570 570
				570 570 570 570
				570 570 570 570
				570 570 570 570
				570 570 570 570
				570 570 570 570
				570 570 570 570
				570 570 570 570
				570 570 570 570
				570 570 570 570
				570 570 570 570
				570 570 570 570
				570 570 570 570
				570 570 570 570
				570 570 570 570
				570 570 570 570
				570 570 570 570
				570 570 570 570
				570 570 570 570
				570 570 570 570
				570 570 570 570>;

			PS_Config_Lmt_PenTipY_FW_Raw_N = <
				(-570) (-570) (-570) (-570)
				(-570) (-570) (-570) (-570)
				(-570) (-570) (-570) (-570)
				(-570) (-570) (-570) (-570)
				(-570) (-570) (-570) (-570)
				(-570) (-570) (-570) (-570)
				(-570) (-570) (-570) (-570)
				(-570) (-570) (-570) (-570)
				(-570) (-570) (-570) (-570)
				(-570) (-570) (-570) (-570)
				(-570) (-570) (-570) (-570)
				(-570) (-570) (-570) (-570)
				(-570) (-570) (-570) (-570)
				(-570) (-570) (-570) (-570)
				(-570) (-570) (-570) (-570)
				(-570) (-570) (-570) (-570)
				(-570) (-570) (-570) (-570)
				(-570) (-570) (-570) (-570)
				(-570) (-570) (-570) (-570)
				(-570) (-570) (-570) (-570)
				(-570) (-570) (-570) (-570)
				(-570) (-570) (-570) (-570)
				(-570) (-570) (-570) (-570)
				(-570) (-570) (-570) (-570)
				(-570) (-570) (-570) (-570)
				(-570) (-570) (-570) (-570)
				(-570) (-570) (-570) (-570)
				(-570) (-570) (-570) (-570)
				(-570) (-570) (-570) (-570)
				(-570) (-570) (-570) (-570)
				(-570) (-570) (-570) (-570)
				(-570) (-570) (-570) (-570)
				(-570) (-570) (-570) (-570)
				(-570) (-570) (-570) (-570)
				(-570) (-570) (-570) (-570)
				(-570) (-570) (-570) (-570)
				(-570) (-570) (-570) (-570)
				(-570) (-570) (-570) (-570)
				(-570) (-570) (-570) (-570)
				(-570) (-570) (-570) (-570)
				(-570) (-570) (-570) (-570)
				(-570) (-570) (-570) (-570)
				(-570) (-570) (-570) (-570)
				(-570) (-570) (-570) (-570)
				(-570) (-570) (-570) (-570)
				(-570) (-570) (-570) (-570)
				(-570) (-570) (-570) (-570)
				(-570) (-570) (-570) (-570)
				(-570) (-570) (-570) (-570)
				(-570) (-570) (-570) (-570)>;

			PS_Config_Lmt_PenRingX_FW_Raw_P = <
				570 570 570 570 570 570 570 570 570 570 570 570 570 570 570 570 570 570 570 570 570 570 570 570 570 570 570 570 570 570 570 570
				570 570 570 570 570 570 570 570 570 570 570 570 570 570 570 570 570 570 570 570 570 570 570 570 570 570 570 570 570 570 570 570
				570 570 570 570 570 570 570 570 570 570 570 570 570 570 570 570 570 570 570 570 570 570 570 570 570 570 570 570 570 570 570 570
				570 570 570 570 570 570 570 570 570 570 570 570 570 570 570 570 570 570 570 570 570 570 570 570 570 570 570 570 570 570 570 570
				570 570 570 570 570 570 570 570 570 570 570 570 570 570 570 570 570 570 570 570 570 570 570 570 570 570 570 570 570 570 570 570
				570 570 570 570 570 570 570 570 570 570 570 570 570 570 570 570 570 570 570 570 570 570 570 570 570 570 570 570 570 570 570 570>;

			PS_Config_Lmt_PenRingX_FW_Raw_N = <
				(-570) (-570) (-570) (-570) (-570) (-570) (-570) (-570) (-570) (-570) (-570) (-570) (-570) (-570) (-570) (-570) (-570) (-570) (-570) (-570) (-570) (-570) (-570) (-570) (-570) (-570) (-570) (-570) (-570) (-570) (-570) (-570)
				(-570) (-570) (-570) (-570) (-570) (-570) (-570) (-570) (-570) (-570) (-570) (-570) (-570) (-570) (-570) (-570) (-570) (-570) (-570) (-570) (-570) (-570) (-570) (-570) (-570) (-570) (-570) (-570) (-570) (-570) (-570) (-570)
				(-570) (-570) (-570) (-570) (-570) (-570) (-570) (-570) (-570) (-570) (-570) (-570) (-570) (-570) (-570) (-570) (-570) (-570) (-570) (-570) (-570) (-570) (-570) (-570) (-570) (-570) (-570) (-570) (-570) (-570) (-570) (-570)
				(-570) (-570) (-570) (-570) (-570) (-570) (-570) (-570) (-570) (-570) (-570) (-570) (-570) (-570) (-570) (-570) (-570) (-570) (-570) (-570) (-570) (-570) (-570) (-570) (-570) (-570) (-570) (-570) (-570) (-570) (-570) (-570)
				(-570) (-570) (-570) (-570) (-570) (-570) (-570) (-570) (-570) (-570) (-570) (-570) (-570) (-570) (-570) (-570) (-570) (-570) (-570) (-570) (-570) (-570) (-570) (-570) (-570) (-570) (-570) (-570) (-570) (-570) (-570) (-570)
				(-570) (-570) (-570) (-570) (-570) (-570) (-570) (-570) (-570) (-570) (-570) (-570) (-570) (-570) (-570) (-570) (-570) (-570) (-570) (-570) (-570) (-570) (-570) (-570) (-570) (-570) (-570) (-570) (-570) (-570) (-570) (-570)>;

			PS_Config_Lmt_PenRingY_FW_Raw_P = <
				570 570 570 570
				570 570 570 570
				570 570 570 570
				570 570 570 570
				570 570 570 570
				570 570 570 570
				570 570 570 570
				570 570 570 570
				570 570 570 570
				570 570 570 570
				570 570 570 570
				570 570 570 570
				570 570 570 570
				570 570 570 570
				570 570 570 570
				570 570 570 570
				570 570 570 570
				570 570 570 570
				570 570 570 570
				570 570 570 570
				570 570 570 570
				570 570 570 570
				570 570 570 570
				570 570 570 570
				570 570 570 570
				570 570 570 570
				570 570 570 570
				570 570 570 570
				570 570 570 570
				570 570 570 570
				570 570 570 570
				570 570 570 570
				570 570 570 570
				570 570 570 570
				570 570 570 570
				570 570 570 570
				570 570 570 570
				570 570 570 570
				570 570 570 570
				570 570 570 570
				570 570 570 570
				570 570 570 570
				570 570 570 570
				570 570 570 570
				570 570 570 570
				570 570 570 570
				570 570 570 570
				570 570 570 570
				570 570 570 570
				570 570 570 570>;

			PS_Config_Lmt_PenRingY_FW_Raw_N = <
				(-570) (-570) (-570) (-570)
				(-570) (-570) (-570) (-570)
				(-570) (-570) (-570) (-570)
				(-570) (-570) (-570) (-570)
				(-570) (-570) (-570) (-570)
				(-570) (-570) (-570) (-570)
				(-570) (-570) (-570) (-570)
				(-570) (-570) (-570) (-570)
				(-570) (-570) (-570) (-570)
				(-570) (-570) (-570) (-570)
				(-570) (-570) (-570) (-570)
				(-570) (-570) (-570) (-570)
				(-570) (-570) (-570) (-570)
				(-570) (-570) (-570) (-570)
				(-570) (-570) (-570) (-570)
				(-570) (-570) (-570) (-570)
				(-570) (-570) (-570) (-570)
				(-570) (-570) (-570) (-570)
				(-570) (-570) (-570) (-570)
				(-570) (-570) (-570) (-570)
				(-570) (-570) (-570) (-570)
				(-570) (-570) (-570) (-570)
				(-570) (-570) (-570) (-570)
				(-570) (-570) (-570) (-570)
				(-570) (-570) (-570) (-570)
				(-570) (-570) (-570) (-570)
				(-570) (-570) (-570) (-570)
				(-570) (-570) (-570) (-570)
				(-570) (-570) (-570) (-570)
				(-570) (-570) (-570) (-570)
				(-570) (-570) (-570) (-570)
				(-570) (-570) (-570) (-570)
				(-570) (-570) (-570) (-570)
				(-570) (-570) (-570) (-570)
				(-570) (-570) (-570) (-570)
				(-570) (-570) (-570) (-570)
				(-570) (-570) (-570) (-570)
				(-570) (-570) (-570) (-570)
				(-570) (-570) (-570) (-570)
				(-570) (-570) (-570) (-570)
				(-570) (-570) (-570) (-570)
				(-570) (-570) (-570) (-570)
				(-570) (-570) (-570) (-570)
				(-570) (-570) (-570) (-570)
				(-570) (-570) (-570) (-570)
				(-570) (-570) (-570) (-570)
				(-570) (-570) (-570) (-570)
				(-570) (-570) (-570) (-570)
				(-570) (-570) (-570) (-570)
				(-570) (-570) (-570) (-570)>;

			PS_Config_Lmt_PenTipX_FW_Diff_P = <
				870 870 870 870 870 870 870 870 870 870 870 870 870 870 870 870 870 870 870 870 870 870 870 870 870 870 870 870 870 870 870 870
				870 870 870 870 870 870 870 870 870 870 870 870 870 870 870 870 870 870 870 870 870 870 870 870 870 870 870 870 870 870 870 870
				870 870 870 870 870 870 870 870 870 870 870 870 870 870 870 870 870 870 870 870 870 870 870 870 870 870 870 870 870 870 870 870
				870 870 870 870 870 870 870 870 870 870 870 870 870 870 870 870 870 870 870 870 870 870 870 870 870 870 870 870 870 870 870 870
				870 870 870 870 870 870 870 870 870 870 870 870 870 870 870 870 870 870 870 870 870 870 870 870 870 870 870 870 870 870 870 870
				870 870 870 870 870 870 870 870 870 870 870 870 870 870 870 870 870 870 870 870 870 870 870 870 870 870 870 870 870 870 870 870>;

			PS_Config_Lmt_PenTipX_FW_Diff_N = <
				(-870) (-870) (-870) (-870) (-870) (-870) (-870) (-870) (-870) (-870) (-870) (-870) (-870) (-870) (-870) (-870) (-870) (-870) (-870) (-870) (-870) (-870) (-870) (-870) (-870) (-870) (-870) (-870) (-870) (-870) (-870) (-870)
				(-870) (-870) (-870) (-870) (-870) (-870) (-870) (-870) (-870) (-870) (-870) (-870) (-870) (-870) (-870) (-870) (-870) (-870) (-870) (-870) (-870) (-870) (-870) (-870) (-870) (-870) (-870) (-870) (-870) (-870) (-870) (-870)
				(-870) (-870) (-870) (-870) (-870) (-870) (-870) (-870) (-870) (-870) (-870) (-870) (-870) (-870) (-870) (-870) (-870) (-870) (-870) (-870) (-870) (-870) (-870) (-870) (-870) (-870) (-870) (-870) (-870) (-870) (-870) (-870)
				(-870) (-870) (-870) (-870) (-870) (-870) (-870) (-870) (-870) (-870) (-870) (-870) (-870) (-870) (-870) (-870) (-870) (-870) (-870) (-870) (-870) (-870) (-870) (-870) (-870) (-870) (-870) (-870) (-870) (-870) (-870) (-870)
				(-870) (-870) (-870) (-870) (-870) (-870) (-870) (-870) (-870) (-870) (-870) (-870) (-870) (-870) (-870) (-870) (-870) (-870) (-870) (-870) (-870) (-870) (-870) (-870) (-870) (-870) (-870) (-870) (-870) (-870) (-870) (-870)
				(-870) (-870) (-870) (-870) (-870) (-870) (-870) (-870) (-870) (-870) (-870) (-870) (-870) (-870) (-870) (-870) (-870) (-870) (-870) (-870) (-870) (-870) (-870) (-870) (-870) (-870) (-870) (-870) (-870) (-870) (-870) (-870)>;

			PS_Config_Lmt_PenTipY_FW_Diff_P = <
				870 870 870 870
				870 870 870 870
				870 870 870 870
				870 870 870 870
				870 870 870 870
				870 870 870 870
				870 870 870 870
				870 870 870 870
				870 870 870 870
				870 870 870 870
				870 870 870 870
				870 870 870 870
				870 870 870 870
				870 870 870 870
				870 870 870 870
				870 870 870 870
				870 870 870 870
				870 870 870 870
				870 870 870 870
				870 870 870 870
				870 870 870 870
				870 870 870 870
				870 870 870 870
				870 870 870 870
				870 870 870 870
				870 870 870 870
				870 870 870 870
				870 870 870 870
				870 870 870 870
				870 870 870 870
				870 870 870 870
				870 870 870 870
				870 870 870 870
				870 870 870 870
				870 870 870 870
				870 870 870 870
				870 870 870 870
				870 870 870 870
				870 870 870 870
				870 870 870 870
				870 870 870 870
				870 870 870 870
				870 870 870 870
				870 870 870 870
				870 870 870 870
				870 870 870 870
				870 870 870 870
				870 870 870 870
				870 870 870 870
				870 870 870 870>;

			PS_Config_Lmt_PenTipY_FW_Diff_N = <
				(-870) (-870) (-870) (-870)
				(-870) (-870) (-870) (-870)
				(-870) (-870) (-870) (-870)
				(-870) (-870) (-870) (-870)
				(-870) (-870) (-870) (-870)
				(-870) (-870) (-870) (-870)
				(-870) (-870) (-870) (-870)
				(-870) (-870) (-870) (-870)
				(-870) (-870) (-870) (-870)
				(-870) (-870) (-870) (-870)
				(-870) (-870) (-870) (-870)
				(-870) (-870) (-870) (-870)
				(-870) (-870) (-870) (-870)
				(-870) (-870) (-870) (-870)
				(-870) (-870) (-870) (-870)
				(-870) (-870) (-870) (-870)
				(-870) (-870) (-870) (-870)
				(-870) (-870) (-870) (-870)
				(-870) (-870) (-870) (-870)
				(-870) (-870) (-870) (-870)
				(-870) (-870) (-870) (-870)
				(-870) (-870) (-870) (-870)
				(-870) (-870) (-870) (-870)
				(-870) (-870) (-870) (-870)
				(-870) (-870) (-870) (-870)
				(-870) (-870) (-870) (-870)
				(-870) (-870) (-870) (-870)
				(-870) (-870) (-870) (-870)
				(-870) (-870) (-870) (-870)
				(-870) (-870) (-870) (-870)
				(-870) (-870) (-870) (-870)
				(-870) (-870) (-870) (-870)
				(-870) (-870) (-870) (-870)
				(-870) (-870) (-870) (-870)
				(-870) (-870) (-870) (-870)
				(-870) (-870) (-870) (-870)
				(-870) (-870) (-870) (-870)
				(-870) (-870) (-870) (-870)
				(-870) (-870) (-870) (-870)
				(-870) (-870) (-870) (-870)
				(-870) (-870) (-870) (-870)
				(-870) (-870) (-870) (-870)
				(-870) (-870) (-870) (-870)
				(-870) (-870) (-870) (-870)
				(-870) (-870) (-870) (-870)
				(-870) (-870) (-870) (-870)
				(-870) (-870) (-870) (-870)
				(-870) (-870) (-870) (-870)
				(-870) (-870) (-870) (-870)
				(-870) (-870) (-870) (-870)>;

			PS_Config_Lmt_PenRingX_FW_Diff_P = <
				870 870 870 870 870 870 870 870 870 870 870 870 870 870 870 870 870 870 870 870 870 870 870 870 870 870 870 870 870 870 870 870
				870 870 870 870 870 870 870 870 870 870 870 870 870 870 870 870 870 870 870 870 870 870 870 870 870 870 870 870 870 870 870 870
				870 870 870 870 870 870 870 870 870 870 870 870 870 870 870 870 870 870 870 870 870 870 870 870 870 870 870 870 870 870 870 870
				870 870 870 870 870 870 870 870 870 870 870 870 870 870 870 870 870 870 870 870 870 870 870 870 870 870 870 870 870 870 870 870
				870 870 870 870 870 870 870 870 870 870 870 870 870 870 870 870 870 870 870 870 870 870 870 870 870 870 870 870 870 870 870 870
				870 870 870 870 870 870 870 870 870 870 870 870 870 870 870 870 870 870 870 870 870 870 870 870 870 870 870 870 870 870 870 870>;

			PS_Config_Lmt_PenRingX_FW_Diff_N = <
				(-870) (-870) (-870) (-870) (-870) (-870) (-870) (-870) (-870) (-870) (-870) (-870) (-870) (-870) (-870) (-870) (-870) (-870) (-870) (-870) (-870) (-870) (-870) (-870) (-870) (-870) (-870) (-870) (-870) (-870) (-870) (-870)
				(-870) (-870) (-870) (-870) (-870) (-870) (-870) (-870) (-870) (-870) (-870) (-870) (-870) (-870) (-870) (-870) (-870) (-870) (-870) (-870) (-870) (-870) (-870) (-870) (-870) (-870) (-870) (-870) (-870) (-870) (-870) (-870)
				(-870) (-870) (-870) (-870) (-870) (-870) (-870) (-870) (-870) (-870) (-870) (-870) (-870) (-870) (-870) (-870) (-870) (-870) (-870) (-870) (-870) (-870) (-870) (-870) (-870) (-870) (-870) (-870) (-870) (-870) (-870) (-870)
				(-870) (-870) (-870) (-870) (-870) (-870) (-870) (-870) (-870) (-870) (-870) (-870) (-870) (-870) (-870) (-870) (-870) (-870) (-870) (-870) (-870) (-870) (-870) (-870) (-870) (-870) (-870) (-870) (-870) (-870) (-870) (-870)
				(-870) (-870) (-870) (-870) (-870) (-870) (-870) (-870) (-870) (-870) (-870) (-870) (-870) (-870) (-870) (-870) (-870) (-870) (-870) (-870) (-870) (-870) (-870) (-870) (-870) (-870) (-870) (-870) (-870) (-870) (-870) (-870)
				(-870) (-870) (-870) (-870) (-870) (-870) (-870) (-870) (-870) (-870) (-870) (-870) (-870) (-870) (-870) (-870) (-870) (-870) (-870) (-870) (-870) (-870) (-870) (-870) (-870) (-870) (-870) (-870) (-870) (-870) (-870) (-870)>;

			PS_Config_Lmt_PenRingY_FW_Diff_P = <
				870 870 870 870
				870 870 870 870
				870 870 870 870
				870 870 870 870
				870 870 870 870
				870 870 870 870
				870 870 870 870
				870 870 870 870
				870 870 870 870
				870 870 870 870
				870 870 870 870
				870 870 870 870
				870 870 870 870
				870 870 870 870
				870 870 870 870
				870 870 870 870
				870 870 870 870
				870 870 870 870
				870 870 870 870
				870 870 870 870
				870 870 870 870
				870 870 870 870
				870 870 870 870
				870 870 870 870
				870 870 870 870
				870 870 870 870
				870 870 870 870
				870 870 870 870
				870 870 870 870
				870 870 870 870
				870 870 870 870
				870 870 870 870
				870 870 870 870
				870 870 870 870
				870 870 870 870
				870 870 870 870
				870 870 870 870
				870 870 870 870
				870 870 870 870
				870 870 870 870
				870 870 870 870
				870 870 870 870
				870 870 870 870
				870 870 870 870
				870 870 870 870
				870 870 870 870
				870 870 870 870
				870 870 870 870
				870 870 870 870
				870 870 870 870>;

			PS_Config_Lmt_PenRingY_FW_Diff_N = <
				(-870) (-870) (-870) (-870)
				(-870) (-870) (-870) (-870)
				(-870) (-870) (-870) (-870)
				(-870) (-870) (-870) (-870)
				(-870) (-870) (-870) (-870)
				(-870) (-870) (-870) (-870)
				(-870) (-870) (-870) (-870)
				(-870) (-870) (-870) (-870)
				(-870) (-870) (-870) (-870)
				(-870) (-870) (-870) (-870)
				(-870) (-870) (-870) (-870)
				(-870) (-870) (-870) (-870)
				(-870) (-870) (-870) (-870)
				(-870) (-870) (-870) (-870)
				(-870) (-870) (-870) (-870)
				(-870) (-870) (-870) (-870)
				(-870) (-870) (-870) (-870)
				(-870) (-870) (-870) (-870)
				(-870) (-870) (-870) (-870)
				(-870) (-870) (-870) (-870)
				(-870) (-870) (-870) (-870)
				(-870) (-870) (-870) (-870)
				(-870) (-870) (-870) (-870)
				(-870) (-870) (-870) (-870)
				(-870) (-870) (-870) (-870)
				(-870) (-870) (-870) (-870)
				(-870) (-870) (-870) (-870)
				(-870) (-870) (-870) (-870)
				(-870) (-870) (-870) (-870)
				(-870) (-870) (-870) (-870)
				(-870) (-870) (-870) (-870)
				(-870) (-870) (-870) (-870)
				(-870) (-870) (-870) (-870)
				(-870) (-870) (-870) (-870)
				(-870) (-870) (-870) (-870)
				(-870) (-870) (-870) (-870)
				(-870) (-870) (-870) (-870)
				(-870) (-870) (-870) (-870)
				(-870) (-870) (-870) (-870)
				(-870) (-870) (-870) (-870)
				(-870) (-870) (-870) (-870)
				(-870) (-870) (-870) (-870)
				(-870) (-870) (-870) (-870)
				(-870) (-870) (-870) (-870)
				(-870) (-870) (-870) (-870)
				(-870) (-870) (-870) (-870)
				(-870) (-870) (-870) (-870)
				(-870) (-870) (-870) (-870)
				(-870) (-870) (-870) (-870)
				(-870) (-870) (-870) (-870)>;

			PS_Config_Diff_Test_Frame = <50>;
		};

		/*for Xiaomi K19A 672C JDI6.497" Truly Module*/
		novatek-mp-criteria-5956@0 {
			#address-cells = <1>;
			#size-cells = <0>;
			compatible = "novatek-mp-criteria-5956";

			/* MP Config */
			IC_X_CFG_SIZE = <16>;
			IC_Y_CFG_SIZE = <36>;
			IC_KEY_CFG_SIZE = <4>;
			X_Channel = <16>;
			Y_Channel = <36>;
			AIN_X = <0 1 2 3 4 5 6 7 8 9 10 11 12 13 14 15>;
			AIN_Y = <0 1 2 3 4 5 6 7 8 9 10 11 12 13 14 15 16 17 18 19 20 21 22 23 24 25 26 27 28 29 30 31 32 33 34 35>;
			//AIN_X = <0 1 2 3 4 5 6 7 8 9 10 11 12 13 14 15 16 17 18 19 20 21 22 23 24 25 26 27 28 29 30 31>;
			//AIN_Y = <0 1 2 3 4 5 6 7 8 9 10 11 12 13 14 15 16 17 18 19 20 21 22 23 24 25 26 27 28 29 30 31 32 33 34 35 36 37 38 39 40 41 42 43 44 45 46 47 48 49>;
			AIN_KEY = <0 1 2 0xFF>;

			/* MP Criteria */
			PS_Config_Lmt_Short_Rawdata_P = <
				14008 14008 14008 14008 14008 14008 14008 14008 14008 14008 14008 14008 14008 14008 14008 14008
				14008 14008 14008 14008 14008 14008 14008 14008 14008 14008 14008 14008 14008 14008 14008 14008
				14008 14008 14008 14008 14008 14008 14008 14008 14008 14008 14008 14008 14008 14008 14008 14008
				14008 14008 14008 14008 14008 14008 14008 14008 14008 14008 14008 14008 14008 14008 14008 14008
				14008 14008 14008 14008 14008 14008 14008 14008 14008 14008 14008 14008 14008 14008 14008 14008
				14008 14008 14008 14008 14008 14008 14008 14008 14008 14008 14008 14008 14008 14008 14008 14008
				14008 14008 14008 14008 14008 14008 14008 14008 14008 14008 14008 14008 14008 14008 14008 14008
				14008 14008 14008 14008 14008 14008 14008 14008 14008 14008 14008 14008 14008 14008 14008 14008
				14008 14008 14008 14008 14008 14008 14008 14008 14008 14008 14008 14008 14008 14008 14008 14008
				14008 14008 14008 14008 14008 14008 14008 14008 14008 14008 14008 14008 14008 14008 14008 14008
				14008 14008 14008 14008 14008 14008 14008 14008 14008 14008 14008 14008 14008 14008 14008 14008
				14008 14008 14008 14008 14008 14008 14008 14008 14008 14008 14008 14008 14008 14008 14008 14008
				14008 14008 14008 14008 14008 14008 14008 14008 14008 14008 14008 14008 14008 14008 14008 14008
				14008 14008 14008 14008 14008 14008 14008 14008 14008 14008 14008 14008 14008 14008 14008 14008
				14008 14008 14008 14008 14008 14008 14008 14008 14008 14008 14008 14008 14008 14008 14008 14008
				14008 14008 14008 14008 14008 14008 14008 14008 14008 14008 14008 14008 14008 14008 14008 14008
				14008 14008 14008 14008 14008 14008 14008 14008 14008 14008 14008 14008 14008 14008 14008 14008
				14008 14008 14008 14008 14008 14008 14008 14008 14008 14008 14008 14008 14008 14008 14008 14008
				14008 14008 14008 14008 14008 14008 14008 14008 14008 14008 14008 14008 14008 14008 14008 14008
				14008 14008 14008 14008 14008 14008 14008 14008 14008 14008 14008 14008 14008 14008 14008 14008
				14008 14008 14008 14008 14008 14008 14008 14008 14008 14008 14008 14008 14008 14008 14008 14008
				14008 14008 14008 14008 14008 14008 14008 14008 14008 14008 14008 14008 14008 14008 14008 14008
				14008 14008 14008 14008 14008 14008 14008 14008 14008 14008 14008 14008 14008 14008 14008 14008
				14008 14008 14008 14008 14008 14008 14008 14008 14008 14008 14008 14008 14008 14008 14008 14008
				14008 14008 14008 14008 14008 14008 14008 14008 14008 14008 14008 14008 14008 14008 14008 14008
				14008 14008 14008 14008 14008 14008 14008 14008 14008 14008 14008 14008 14008 14008 14008 14008
				14008 14008 14008 14008 14008 14008 14008 14008 14008 14008 14008 14008 14008 14008 14008 14008
				14008 14008 14008 14008 14008 14008 14008 14008 14008 14008 14008 14008 14008 14008 14008 14008
				14008 14008 14008 14008 14008 14008 14008 14008 14008 14008 14008 14008 14008 14008 14008 14008
				14008 14008 14008 14008 14008 14008 14008 14008 14008 14008 14008 14008 14008 14008 14008 14008
				14008 14008 14008 14008 14008 14008 14008 14008 14008 14008 14008 14008 14008 14008 14008 14008
				14008 14008 14008 14008 14008 14008 14008 14008 14008 14008 14008 14008 14008 14008 14008 14008
				14008 14008 14008 14008 14008 14008 14008 14008 14008 14008 14008 14008 14008 14008 14008 14008
				14008 14008 14008 14008 14008 14008 14008 14008 14008 14008 14008 14008 14008 14008 14008 14008
				14008 14008 14008 14008 14008 14008 14008 14008 14008 14008 14008 14008 14008 14008 14008 14008
				14008 14008 14008 14008 14008 14008 14008 14008 14008 14008 14008 14008 14008 14008 14008 14008
				14008 14008 14008>;

			PS_Config_Lmt_Short_Rawdata_N = <
				10100	10100	10100	10100	10100	10100	10100	10100	10100	10100	10100	10100	10100	10100	10100	10100
				10100	10100	10100	10100	10100	10100	10100	10100	10100	10100	10100	10100	10100	10100	10100	10100
				10100	10100	10100	10100	10100	10100	10100	10100	10100	10100	10100	10100	10100	10100	10100	10100
				10100	10100	10100	10100	10100	10100	10100	10100	10100	10100	10100	10100	10100	10100	10100	10100
				10100	10100	10100	10100	10100	10100	10100	10100	10100	10100	10100	10100	10100	10100	10100	10100
				10100	10100	10100	10100	10100	10100	10100	10100	10100	10100	10100	10100	10100	10100	10100	10100
				10100	10100	10100	10100	10100	10100	10100	10100	10100	10100	10100	10100	10100	10100	10100	10100
				10100	10100	10100	10100	10100	10100	10100	10100	10100	10100	10100	10100	10100	10100	10100	10100
				10100	10100	10100	10100	10100	10100	10100	10100	10100	10100	10100	10100	10100	10100	10100	10100
				10100	10100	10100	10100	10100	10100	10100	10100	10100	10100	10100	10100	10100	10100	10100	10100
				10100	10100	10100	10100	10100	10100	10100	10100	10100	10100	10100	10100	10100	10100	10100	10100
				10100	10100	10100	10100	10100	10100	10100	10100	10100	10100	10100	10100	10100	10100	10100	10100
				10100	10100	10100	10100	10100	10100	10100	10100	10100	10100	10100	10100	10100	10100	10100	10100
				10100	10100	10100	10100	10100	10100	10100	10100	10100	10100	10100	10100	10100	10100	10100	10100
				10100	10100	10100	10100	10100	10100	10100	10100	10100	10100	10100	10100	10100	10100	10100	10100
				10100	10100	10100	10100	10100	10100	10100	10100	10100	10100	10100	10100	10100	10100	10100	10100
				10100	10100	10100	10100	10100	10100	10100	10100	10100	10100	10100	10100	10100	10100	10100	10100
				10100	10100	10100	10100	10100	10100	10100	10100	10100	10100	10100	10100	10100	10100	10100	10100
				10100	10100	10100	10100	10100	10100	10100	10100	10100	10100	10100	10100	10100	10100	10100	10100
				10100	10100	10100	10100	10100	10100	10100	10100	10100	10100	10100	10100	10100	10100	10100	10100
				10100	10100	10100	10100	10100	10100	10100	10100	10100	10100	10100	10100	10100	10100	10100	10100
				10100	10100	10100	10100	10100	10100	10100	10100	10100	10100	10100	10100	10100	10100	10100	10100
				10100	10100	10100	10100	10100	10100	10100	10100	10100	10100	10100	10100	10100	10100	10100	10100
				10100	10100	10100	10100	10100	10100	10100	10100	10100	10100	10100	10100	10100	10100	10100	10100
				10100	10100	10100	10100	10100	10100	10100	10100	10100	10100	10100	10100	10100	10100	10100	10100
				10100	10100	10100	10100	10100	10100	10100	10100	10100	10100	10100	10100	10100	10100	10100	10100
				10100	10100	10100	10100	10100	10100	10100	10100	10100	10100	10100	10100	10100	10100	10100	10100
				10100	10100	10100	10100	10100	10100	10100	10100	10100	10100	10100	10100	10100	10100	10100	10100
				10100	10100	10100	10100	10100	10100	10100	10100	10100	10100	10100	10100	10100	10100	10100	10100
				10100	10100	10100	10100	10100	10100	10100	10100	10100	10100	10100	10100	10100	10100	10100	10100
				10100	10100	10100	10100	10100	10100	10100	10100	10100	10100	10100	10100	10100	10100	10100	10100
				10100	10100	10100	10100	10100	10100	10100	10100	10100	10100	10100	10100	10100	10100	10100	10100
				10100	10100	10100	10100	10100	10100	10100	10100	10100	10100	10100	10100	10100	10100	10100	10100
				10100	10100	10100	10100	10100	10100	10100	10100	10100	10100	10100	10100	10100	10100	10100	10100
				10100	10100	10100	10100	10100	10100	10100	10100	10100	10100	10100	10100	10100	10100	10100	10100
				10100	10100	10100	10100	10100	10100	10100	10100	10100	10100	10100	10100	10100	10100	10100	10100
				10000 10000 10000>;

			PS_Config_Lmt_Open_Rawdata_P = <
				3729	4214	4151	4085	4054	4044	4055	3952	4120	4258	4244	4257	4200	4212	4221	3725
				3970	4229	4139	4075	4050	4039	4047	3995	4172	4254	4236	4257	4198	4215	4247	3960
				4170	4180	4086	4013	3995	3981	3994	3981	4173	4181	4173	4187	4137	4159	4211	4151
				4130	4139	4047	3964	3942	3927	3943	3899	4141	4156	4146	4165	4125	4144	4205	4117
				4076	4095	3991	3915	3904	3883	3897	3879	4032	4051	4046	4057	4019	4060	4113	4067
				4079	4102	3991	3925	3904	3887	3900	3880	4004	4026	4022	4027	4002	4046	4097	4051
				4025	4054	3946	3869	3852	3838	3847	3829	3943	3967	3956	3974	3950	3991	4051	4008
				4020	4055	3943	3859	3845	3837	3815	3826	3921	3945	3932	3950	3927	3970	4005	3990
				3973	4005	3899	3816	3805	3788	3803	3785	3904	3922	3913	3925	3913	3956	4027	3983
				3952	3983	3876	3792	3782	3764	3778	3756	3875	3890	3883	3892	3887	3929	4006	3960
				3927	3971	3855	3778	3761	3725	3763	3740	3824	3850	3840	3845	3848	3869	3970	3931
				3894	3932	3815	3743	3726	3712	3726	3704	3777	3803	3794	3799	3805	3857	3934	3899
				3854	3893	3784	3703	3683	3675	3687	3663	3732	3760	3745	3757	3773	3815	3900	3864
				3834	3875	3771	3689	3672	3670	3676	3656	3693	3719	3704	3715	3729	3775	3861	3823
				3794	3827	3728	3642	3605	3619	3633	3607	3655	3677	3669	3675	3673	3749	3834	3798
				3756	3788	3691	3607	3592	3581	3593	3571	3612	3631	3624	3630	3655	3707	3801	3760
				3724	3759	3663	3579	3564	3557	3565	3544	3567	3592	3582	3588	3607	3673	3763	3728
				3673	3708	3607	3508	3512	3502	3512	3493	3521	3549	3539	3525	3565	3635	3725	3693
				3641	3675	3584	3518	3505	3500	3505	3484	3460	3486	3477	3483	3505	3593	3693	3665
				3612	3645	3551	3487	3473	3466	3470	3455	3417	3439	3431	3442	3459	3550	3652	3624
				3571	3596	3502	3445	3432	3423	3427	3409	3360	3375	3372	3379	3397	3488	3599	3570
				3533	3557	3446	3404	3393	3383	3386	3372	3329	3343	3326	3348	3369	3460	3574	3546
				3484	3511	3411	3354	3344	3334	3333	3318	3273	3291	3292	3298	3316	3407	3523	3504
				3432	3455	3355	3301	3291	3284	3281	3269	3211	3229	3235	3238	3259	3353	3470	3448
				3395	3414	3319	3257	3253	3248	3243	3231	3162	3176	3178	3186	3204	3295	3421	3403
				3333	3336	3260	3194	3193	3190	3186	3172	3113	3115	3129	3138	3157	3248	3376	3358
				3311	3326	3229	3165	3166	3159	3158	3143	3066	3078	3082	3088	3108	3197	3325	3313
				3260	3274	3176	3110	3115	3106	3103	3088	3014	3026	3033	3036	3056	3145	3278	3267
				3187	3220	3116	3054	3059	3054	3049	3040	2958	2983	2986	2991	3010	3103	3231	3229
				3165	3183	3077	3015	3019	3015	3008	2998	2895	2913	2914	2920	2938	3031	3158	3159
				3103	3119	3015	2951	2961	2955	2949	2937	2853	2867	2871	2875	2893	2982	3113	3116
				3067	3084	2982	2913	2923	2921	2916	2903	2797	2812	2815	2822	2839	2928	3060	3066
				3060	3075	2968	2899	2913	2910	2906	2892	2773	2786	2791	2793	2811	2907	3040	3049
				2997	3014	2905	2837	2850	2846	2846	2832	2730	2742	2746	2748	2765	2863	2997	3005
				2752	3019	2905	2837	2854	2851	2851	2839	2710	2727	2725	2727	2746	2844	2982	2744
				2891	2954	2836	2769	2786	2786	2788	2777	2643	2661	2657	2657	2676	2776	2913	2882
				5120 5120 5120>;

			PS_Config_Lmt_Open_Rawdata_N = <
				1598	1806	1779	1750	1737	1733	1738	1693	1765	1825	1819	1824	1800	1805	1809	1596
				1701	1812	1774	1746	1735	1731	1734	1712	1788	1823	1815	1824	1799	1806	1820	1697
				1787	1791	1751	1720	1712	1706	1711	1706	1788	1792	1788	1794	1773	1782	1804	1779
				1770	1774	1734	1699	1689	1683	1690	1671	1774	1781	1777	1785	1768	1776	1802	1764
				1747	1755	1710	1678	1673	1664	1670	1662	1728	1736	1734	1738	1722	1740	1762	1743
				1748	1758	1710	1682	1673	1666	1671	1663	1716	1725	1723	1726	1715	1734	1756	1736
				1725	1737	1691	1658	1651	1645	1648	1641	1690	1700	1695	1703	1693	1710	1736	1717
				1723	1738	1690	1654	1648	1644	1635	1639	1680	1690	1685	1693	1683	1701	1716	1710
				1702	1716	1671	1635	1630	1623	1630	1622	1673	1681	1677	1682	1677	1695	1726	1707
				1693	1707	1661	1625	1621	1613	1619	1609	1660	1667	1664	1668	1666	1684	1717	1697
				1683	1702	1652	1619	1612	1596	1612	1603	1639	1650	1645	1648	1649	1658	1701	1684
				1669	1685	1635	1604	1597	1591	1597	1587	1618	1630	1626	1628	1630	1653	1686	1671
				1651	1668	1621	1587	1578	1575	1580	1570	1599	1611	1605	1610	1617	1635	1671	1656
				1643	1660	1616	1581	1573	1573	1575	1567	1582	1594	1587	1592	1598	1618	1654	1638
				1626	1640	1597	1561	1545	1551	1557	1546	1566	1576	1572	1575	1574	1606	1643	1627
				1609	1623	1582	1546	1539	1534	1540	1530	1548	1556	1553	1555	1566	1588	1629	1611
				1596	1611	1570	1534	1527	1524	1528	1519	1528	1539	1535	1537	1546	1574	1612	1597
				1574	1589	1546	1503	1505	1501	1505	1497	1509	1521	1516	1510	1528	1558	1596	1582
				1560	1575	1536	1507	1502	1500	1502	1493	1483	1494	1490	1492	1502	1540	1582	1570
				1548	1562	1522	1494	1488	1485	1487	1480	1464	1474	1470	1475	1482	1521	1565	1553
				1530	1541	1501	1476	1471	1467	1468	1461	1440	1446	1445	1448	1456	1495	1542	1530
				1514	1524	1477	1459	1454	1450	1451	1445	1426	1432	1425	1435	1444	1483	1531	1519
				1493	1504	1462	1437	1433	1429	1428	1422	1402	1410	1411	1413	1421	1460	1510	1501
				1471	1480	1438	1414	1410	1407	1406	1401	1376	1384	1386	1387	1396	1437	1487	1477
				1455	1463	1422	1396	1394	1392	1390	1384	1355	1361	1362	1365	1373	1412	1466	1458
				1428	1429	1397	1369	1368	1367	1365	1359	1334	1335	1341	1345	1353	1392	1447	1439
				1419	1425	1384	1356	1357	1354	1353	1347	1314	1319	1321	1323	1332	1370	1425	1420
				1397	1403	1361	1333	1335	1331	1330	1323	1291	1297	1300	1301	1309	1348	1405	1400
				1366	1380	1335	1309	1311	1309	1306	1303	1267	1278	1279	1282	1290	1330	1384	1384
				1356	1364	1318	1292	1294	1292	1289	1285	1240	1248	1249	1251	1259	1299	1353	1354
				1330	1336	1292	1264	1269	1266	1264	1258	1222	1228	1230	1232	1240	1278	1334	1335
				1314	1321	1278	1248	1252	1252	1249	1244	1198	1205	1206	1209	1216	1255	1311	1314
				1311	1318	1272	1242	1248	1247	1245	1239	1188	1194	1196	1197	1204	1246	1303	1306
				1284	1291	1245	1216	1221	1219	1219	1213	1170	1175	1177	1177	1185	1227	1284	1288
				1179	1294	1245	1216	1223	1222	1222	1216	1161	1168	1168	1168	1177	1219	1278	1176
				1239	1266	1215	1186	1194	1194	1195	1190	1132	1140	1138	1138	1147	1189	1248	1235
				(-511) (-511) (-511)>;

			PS_Config_Lmt_FW_Rawdata_P = <
				1124	1121	1122	1122	1114	1121	1121	1124	1124	1125	1127	1121	1120	1114	1113	1108
				1124	1106	1107	1113	1111	1111	1114	1118	1134	1146	1142	1138	1134	1128	1114	1145
				1117	1122	1122	1127	1121	1120	1118	1128	1114	1111	1113	1114	1111	1110	1114	1120
				1118	1118	1117	1118	1115	1120	1115	1115	1117	1121	1124	1122	1122	1128	1134	1124
				1106	1107	1114	1108	1127	1134	1106	1125	1124	1115	1121	1115	1120	1122	1120	1128
				1124	1107	1110	1110	1104	1111	1108	1108	1099	1100	1111	1114	1106	1117	1111	1110
				1124	1121	1117	1124	1124	1122	1122	1121	1114	1118	1114	1118	1115	1114	1114	1125
				1117	1118	1122	1122	1127	1132	1117	1115	1108	1111	1113	1108	1111	1124	1122	1114
				1110	1108	1113	1113	1107	1108	1108	1107	1113	1118	1131	1129	1131	1132	1121	1114
				1121	1115	1117	1115	1115	1118	1117	1127	1131	1129	1125	1121	1121	1118	1117	1124
				1104	1103	1101	1101	1101	1099	1101	1103	1127	1129	1121	1122	1115	1110	1110	1127
				1115	1125	1122	1124	1124	1118	1125	1129	1104	1106	1110	1111	1117	1115	1124	1108
				1121	1113	1118	1114	1113	1118	1117	1120	1101	1101	1100	1106	1106	1106	1117	1117
				1131	1099	1104	1099	1113	1104	1111	1114	1113	1113	1115	1099	1120	1115	1134	1117
				1110	1115	1106	1114	1110	1106	1108	1110	1113	1110	1101	1107	1113	1106	1111	1117
				1114	1121	1111	1120	1118	1115	1114	1120	1121	1124	1117	1115	1120	1122	1117	1118
				1128	1118	1127	1118	1121	1122	1124	1122	1115	1120	1121	1121	1122	1118	1120	1121
				1120	1118	1120	1115	1118	1118	1118	1115	1128	1127	1118	1107	1114	1113	1108	1129
				1128	1135	1136	1134	1131	1129	1129	1125	1118	1115	1117	1117	1118	1121	1125	1113
				1111	1114	1117	1118	1120	1122	1115	1117	1110	1108	1110	1108	1111	1113	1108	1120
				1108	1120	1108	1110	1111	1111	1111	1110	1121	1117	1120	1121	1122	1118	1118	1113
				1125	1110	1117	1101	1107	1111	1115	1124	1122	1121	1125	1122	1124	1124	1120	1121
				1122	1113	1113	1114	1117	1122	1121	1124	1121	1120	1117	1113	1115	1118	1114	1117
				1125	1117	1124	1124	1121	1121	1124	1125	1115	1118	1114	1104	1111	1110	1106	1129
				1113	1118	1124	1115	1118	1120	1120	1117	1114	1125	1121	1122	1121	1122	1125	1125
				1122	1118	1117	1122	1118	1117	1117	1129	1107	1100	1100	1100	1099	1097	1100	1125
				1115	1108	1114	1111	1108	1110	1111	1113	1115	1111	1111	1127	1122	1118	1120	1111
				1127	1117	1114	1121	1118	1117	1118	1115	1110	1108	1108	1108	1107	1104	1106	1110
				1097	1094	1099	1100	1113	1096	1097	1097	1122	1120	1117	1111	1113	1114	1120	1124
				1134	1127	1128	1124	1124	1127	1131	1099	1118	1129	1129	1120	1124	1125	1129	1122
				1099	1135	1138	1136	1135	1128	1131	1096	1117	1111	1110	1122	1122	1120	1114	1110
				1129	1106	1120	1121	1114	1124	1124	1100	1111	1111	1114	1110	1110	1113	1111	1117
				1120	1134	1134	1132	1127	1134	1125	1100	1122	1110	1115	1124	1113	1129	1122	1104
				1118	1106	1113	1120	1111	1121	1122	1115	1115	1107	1111	1120	1113	1117	1124	1117
				1118	1118	1125	1121	1118	1118	1121	1115	1122	1111	1107	1101	1101	1100	1106	1108
				1135	1120	1132	1134	1121	1118	1120	1124	1127	1124	1121	1115	1118	1115	1114	1110
				2560 2560 2560>;

			PS_Config_Lmt_FW_Rawdata_N = <
				481	480	481	481	477	480	480	481	481	482	483	480	480	477	477	475
				481	474	474	477	476	476	477	479	486	491	489	487	486	483	477	490
				478	481	481	483	480	480	479	483	477	476	477	477	476	475	477	480
				479	479	478	479	478	480	478	478	478	480	481	481	481	483	486	481
				474	474	477	475	483	486	474	482	481	478	480	478	480	481	480	483
				481	474	475	475	473	476	475	475	471	471	476	477	474	478	476	475
				481	480	478	481	481	481	481	480	477	479	477	479	478	477	477	482
				478	479	481	481	483	485	478	478	475	476	477	475	476	481	481	477
				475	475	477	477	474	475	475	474	477	479	484	484	484	485	480	477
				480	478	478	478	478	479	478	483	484	484	482	480	480	479	478	481
				473	472	472	472	472	471	472	472	483	484	480	481	478	475	475	483
				478	482	481	481	481	479	482	484	473	474	475	476	478	478	481	475
				480	477	479	477	477	479	478	480	472	472	471	474	474	474	478	478
				484	471	473	471	477	473	476	477	477	477	478	471	480	478	486	478
				475	478	474	477	475	474	475	475	477	475	472	474	477	474	476	478
				477	480	476	480	479	478	477	480	480	481	478	478	480	481	478	479
				483	479	483	479	480	481	481	481	478	480	480	480	481	479	480	480
				480	479	480	478	479	479	479	478	483	483	479	474	477	477	475	484
				483	486	487	486	484	484	484	482	479	478	478	478	479	480	482	477
				476	477	478	479	480	481	478	478	475	475	475	475	476	477	475	480
				475	480	475	475	476	476	476	475	480	478	480	480	481	479	479	477
				482	475	478	472	474	476	478	481	481	480	482	481	481	481	480	480
				481	477	477	477	478	481	480	481	480	480	478	477	478	479	477	478
				482	478	481	481	480	480	481	482	478	479	477	473	476	475	474	484
				477	479	481	478	479	480	480	478	477	482	480	481	480	481	482	482
				481	479	478	481	479	478	478	484	474	471	471	471	471	470	471	482
				478	475	477	476	475	475	476	477	478	476	476	483	481	479	480	476
				483	478	477	480	479	478	479	478	475	475	475	475	474	473	474	475
				470	469	471	471	477	469	470	470	481	480	478	476	477	477	480	481
				486	483	483	481	481	483	484	471	479	484	484	480	481	482	484	481
				471	486	487	487	486	483	484	469	478	476	475	481	481	480	477	475
				484	474	480	480	477	481	481	471	476	476	477	475	475	477	476	478
				480	486	486	485	483	486	482	471	481	475	478	481	477	484	481	473
				479	474	477	480	476	480	481	478	478	474	476	480	477	478	481	478
				479	479	482	480	479	479	480	478	481	476	474	472	472	471	474	475
				486	480	485	486	480	479	480	481	483	481	480	478	479	478	477	475
				240 240 240>;

			PS_Config_Lmt_FW_CC_P = <
				49	49	49	49	49	49	49	49	49	49	49	49	49	49	49	51
				51	49	49	49	49	49	49	49	49	49	49	49	49	49	49	49
				49	49	49	49	49	49	49	49	49	49	49	49	49	49	49	51
				51	49	49	49	49	49	49	49	49	51	49	49	49	49	49	49
				49	49	49	49	49	49	49	49	49	51	49	49	49	49	49	51
				51	49	49	51	49	49	51	51	51	51	49	49	51	49	49	51
				49	49	49	49	49	49	49	49	51	51	49	49	51	49	49	51
				51	51	51	51	49	49	51	51	51	51	51	51	51	51	49	51
				49	49	49	49	49	49	49	49	51	51	51	51	51	49	49	51
				51	51	51	51	51	51	51	51	51	51	51	51	51	51	49	51
				49	49	49	49	49	49	49	49	51	51	51	51	51	51	51	51
				51	49	49	49	49	49	51	51	51	51	51	51	51	51	49	51
				49	49	49	49	49	49	49	49	51	51	49	49	49	49	49	51
				51	51	51	51	51	51	51	51	51	51	51	51	51	51	49	51
				49	49	49	49	49	49	49	49	51	51	51	51	49	51	49	51
				51	51	51	51	51	51	51	51	51	51	51	51	51	51	51	51
				49	49	49	49	49	49	49	49	51	49	49	49	49	49	49	51
				51	51	51	51	51	51	51	51	51	51	51	51	51	51	51	51
				49	49	49	49	49	49	49	49	51	49	49	49	49	49	49	51
				51	51	51	51	51	51	51	51	51	51	51	51	51	51	51	51
				51	49	49	49	49	49	51	51	51	51	51	51	51	51	51	51
				51	51	51	51	51	51	51	51	51	51	51	51	51	51	51	51
				51	49	49	49	49	49	49	49	51	51	51	51	51	51	51	51
				51	49	51	51	51	51	51	51	51	51	49	49	49	49	49	51
				51	49	49	49	49	49	49	49	51	51	51	51	51	51	51	51
				51	51	51	51	51	51	51	51	51	51	51	51	51	51	51	51
				51	51	51	51	51	51	51	51	51	51	51	51	51	51	51	51
				51	51	51	51	51	51	51	51	51	51	51	51	51	51	51	51
				51	51	51	51	49	51	51	51	51	51	51	51	51	51	51	51
				51	51	51	51	51	51	51	52	51	51	51	51	51	51	51	51
				51	51	51	51	49	51	51	51	51	51	51	51	51	51	51	51
				51	51	51	51	51	51	51	52	51	51	51	51	51	51	51	51
				51	51	51	51	51	51	51	51	51	51	51	51	51	51	51	51
				51	51	51	51	51	51	51	52	51	51	51	51	51	51	51	51
				51	49	51	51	51	51	51	51	51	51	51	51	51	51	51	51
				52	51	51	51	51	51	51	52	51	51	51	51	51	51	51	52
				314 314 314>;

			PS_Config_Lmt_FW_CC_N = <
				22	22	22	22	22	22	22	22	22	22	22	22	22	22	22	22
				22	22	22	22	22	22	22	22	22	22	22	22	22	22	22	22
				22	22	22	22	22	22	22	22	22	22	22	22	22	22	22	22
				22	22	22	22	22	22	22	22	22	22	22	22	22	22	22	22
				22	22	22	22	22	22	22	22	22	22	22	22	22	22	22	22
				22	22	22	22	22	22	22	22	22	22	22	22	22	22	22	22
				22	22	22	22	22	22	22	22	22	22	22	22	22	22	22	22
				22	22	22	22	22	22	22	22	22	22	22	22	22	22	22	22
				22	22	22	22	22	22	22	22	22	22	22	22	22	22	22	22
				22	22	22	22	22	22	22	22	22	22	22	22	22	22	22	22
				22	22	22	22	22	22	22	22	22	22	22	22	22	22	22	22
				22	22	22	22	22	22	22	22	22	22	22	22	22	22	22	22
				22	22	22	22	22	22	22	22	22	22	22	22	22	22	22	22
				22	22	22	22	22	22	22	22	22	22	22	22	22	22	22	22
				22	22	22	22	22	22	22	22	22	22	22	22	22	22	22	22
				22	22	22	22	22	22	22	22	22	22	22	22	22	22	22	22
				22	22	22	22	22	22	22	22	22	22	22	22	22	22	22	22
				22	22	22	22	22	22	22	22	22	22	22	22	22	22	22	22
				22	22	22	22	22	22	22	22	22	22	22	22	22	22	22	22
				22	22	22	22	22	22	22	22	22	22	22	22	22	22	22	22
				22	22	22	22	22	22	22	22	22	22	22	22	22	22	22	22
				22	22	22	22	22	22	22	22	22	22	22	22	22	22	22	22
				22	22	22	22	22	22	22	22	22	22	22	22	22	22	22	22
				22	22	22	22	22	22	22	22	22	22	22	22	22	22	22	22
				22	22	22	22	22	22	22	22	22	22	22	22	22	22	22	22
				22	22	22	22	22	22	22	22	22	22	22	22	22	22	22	22
				22	22	22	22	22	22	22	22	22	22	22	22	22	22	22	22
				22	22	22	22	22	22	22	22	22	22	22	22	22	22	22	22
				22	22	22	22	22	22	22	22	22	22	22	22	22	22	22	22
				22	22	22	22	22	22	22	23	22	22	22	22	22	22	22	22
				22	22	22	22	22	22	22	22	22	22	22	22	22	22	22	22
				22	22	22	22	22	22	22	23	22	22	22	22	22	22	22	22
				22	22	22	22	22	22	22	22	22	22	22	22	22	22	22	22
				22	22	22	22	22	22	22	23	22	22	22	22	22	22	22	22
				22	22	22	22	22	22	22	22	22	22	22	22	22	22	22	22
				23	22	22	22	22	22	22	23	22	22	22	22	22	22	22	23
				0 0 0>;

			PS_Config_Lmt_FW_Diff_P = <
				50	50	50	50	50	50	50	50	50	50	50	50	50	50	50	50
				50	50	50	50	50	50	50	50	50	50	50	50	50	50	50	50
				50	50	50	50	50	50	50	50	50	50	50	50	50	50	50	50
				50	50	50	50	50	50	50	50	50	50	50	50	50	50	50	50
				50	50	50	50	50	50	50	50	50	50	50	50	50	50	50	50
				50	50	50	50	50	50	50	50	50	50	50	50	50	50	50	50
				50	50	50	50	50	50	50	50	50	50	50	50	50	50	50	50
				50	50	50	50	50	50	50	50	50	50	50	50	50	50	50	50
				50	50	50	50	50	50	50	50	50	50	50	50	50	50	50	50
				50	50	50	50	50	50	50	50	50	50	50	50	50	50	50	50
				50	50	50	50	50	50	50	50	50	50	50	50	50	50	50	50
				50	50	50	50	50	50	50	50	50	50	50	50	50	50	50	50
				50	50	50	50	50	50	50	50	50	50	50	50	50	50	50	50
				50	50	50	50	50	50	50	50	50	50	50	50	50	50	50	50
				50	50	50	50	50	50	50	50	50	50	50	50	50	50	50	50
				50	50	50	50	50	50	50	50	50	50	50	50	50	50	50	50
				50	50	50	50	50	50	50	50	50	50	50	50	50	50	50	50
				50	50	50	50	50	50	50	50	50	50	50	50	50	50	50	50
				50	50	50	50	50	50	50	50	50	50	50	50	50	50	50	50
				50	50	50	50	50	50	50	50	50	50	50	50	50	50	50	50
				50	50	50	50	50	50	50	50	50	50	50	50	50	50	50	50
				50	50	50	50	50	50	50	50	50	50	50	50	50	50	50	50
				50	50	50	50	50	50	50	50	50	50	50	50	50	50	50	50
				50	50	50	50	50	50	50	50	50	50	50	50	50	50	50	50
				50	50	50	50	50	50	50	50	50	50	50	50	50	50	50	50
				50	50	50	50	50	50	50	50	50	50	50	50	50	50	50	50
				50	50	50	50	50	50	50	50	50	50	50	50	50	50	50	50
				50	50	50	50	50	50	50	50	50	50	50	50	50	50	50	50
				50	50	50	50	50	50	50	50	50	50	50	50	50	50	50	50
				50	50	50	50	50	50	50	50	50	50	50	50	50	50	50	50
				50	50	50	50	50	50	50	50	50	50	50	50	50	50	50	50
				50	50	50	50	50	50	50	50	50	50	50	50	50	50	50	50
				50	50	50	50	50	50	50	50	50	50	50	50	50	50	50	50
				50	50	50	50	50	50	50	50	50	50	50	50	50	50	50	50
				50	50	50	50	50	50	50	50	50	50	50	50	50	50	50	50
				50	50	50	50	50	50	50	50	50	50	50	50	50	50	50	50
				75 75 75>;

			PS_Config_Lmt_FW_Diff_N = <
				(-50)	(-50)	(-50)	(-50)	(-50)	(-50)	(-50)	(-50)	(-50)	(-50)	(-50)	(-50)	(-50)	(-50)	(-50)	(-50)
				(-50)	(-50)	(-50)	(-50)	(-50)	(-50)	(-50)	(-50)	(-50)	(-50)	(-50)	(-50)	(-50)	(-50)	(-50)	(-50)
				(-50)	(-50)	(-50)	(-50)	(-50)	(-50)	(-50)	(-50)	(-50)	(-50)	(-50)	(-50)	(-50)	(-50)	(-50)	(-50)
				(-50)	(-50)	(-50)	(-50)	(-50)	(-50)	(-50)	(-50)	(-50)	(-50)	(-50)	(-50)	(-50)	(-50)	(-50)	(-50)
				(-50)	(-50)	(-50)	(-50)	(-50)	(-50)	(-50)	(-50)	(-50)	(-50)	(-50)	(-50)	(-50)	(-50)	(-50)	(-50)
				(-50)	(-50)	(-50)	(-50)	(-50)	(-50)	(-50)	(-50)	(-50)	(-50)	(-50)	(-50)	(-50)	(-50)	(-50)	(-50)
				(-50)	(-50)	(-50)	(-50)	(-50)	(-50)	(-50)	(-50)	(-50)	(-50)	(-50)	(-50)	(-50)	(-50)	(-50)	(-50)
				(-50)	(-50)	(-50)	(-50)	(-50)	(-50)	(-50)	(-50)	(-50)	(-50)	(-50)	(-50)	(-50)	(-50)	(-50)	(-50)
				(-50)	(-50)	(-50)	(-50)	(-50)	(-50)	(-50)	(-50)	(-50)	(-50)	(-50)	(-50)	(-50)	(-50)	(-50)	(-50)
				(-50)	(-50)	(-50)	(-50)	(-50)	(-50)	(-50)	(-50)	(-50)	(-50)	(-50)	(-50)	(-50)	(-50)	(-50)	(-50)
				(-50)	(-50)	(-50)	(-50)	(-50)	(-50)	(-50)	(-50)	(-50)	(-50)	(-50)	(-50)	(-50)	(-50)	(-50)	(-50)
				(-50)	(-50)	(-50)	(-50)	(-50)	(-50)	(-50)	(-50)	(-50)	(-50)	(-50)	(-50)	(-50)	(-50)	(-50)	(-50)
				(-50)	(-50)	(-50)	(-50)	(-50)	(-50)	(-50)	(-50)	(-50)	(-50)	(-50)	(-50)	(-50)	(-50)	(-50)	(-50)
				(-50)	(-50)	(-50)	(-50)	(-50)	(-50)	(-50)	(-50)	(-50)	(-50)	(-50)	(-50)	(-50)	(-50)	(-50)	(-50)
				(-50)	(-50)	(-50)	(-50)	(-50)	(-50)	(-50)	(-50)	(-50)	(-50)	(-50)	(-50)	(-50)	(-50)	(-50)	(-50)
				(-50)	(-50)	(-50)	(-50)	(-50)	(-50)	(-50)	(-50)	(-50)	(-50)	(-50)	(-50)	(-50)	(-50)	(-50)	(-50)
				(-50)	(-50)	(-50)	(-50)	(-50)	(-50)	(-50)	(-50)	(-50)	(-50)	(-50)	(-50)	(-50)	(-50)	(-50)	(-50)
				(-50)	(-50)	(-50)	(-50)	(-50)	(-50)	(-50)	(-50)	(-50)	(-50)	(-50)	(-50)	(-50)	(-50)	(-50)	(-50)
				(-50)	(-50)	(-50)	(-50)	(-50)	(-50)	(-50)	(-50)	(-50)	(-50)	(-50)	(-50)	(-50)	(-50)	(-50)	(-50)
				(-50)	(-50)	(-50)	(-50)	(-50)	(-50)	(-50)	(-50)	(-50)	(-50)	(-50)	(-50)	(-50)	(-50)	(-50)	(-50)
				(-50)	(-50)	(-50)	(-50)	(-50)	(-50)	(-50)	(-50)	(-50)	(-50)	(-50)	(-50)	(-50)	(-50)	(-50)	(-50)
				(-50)	(-50)	(-50)	(-50)	(-50)	(-50)	(-50)	(-50)	(-50)	(-50)	(-50)	(-50)	(-50)	(-50)	(-50)	(-50)
				(-50)	(-50)	(-50)	(-50)	(-50)	(-50)	(-50)	(-50)	(-50)	(-50)	(-50)	(-50)	(-50)	(-50)	(-50)	(-50)
				(-50)	(-50)	(-50)	(-50)	(-50)	(-50)	(-50)	(-50)	(-50)	(-50)	(-50)	(-50)	(-50)	(-50)	(-50)	(-50)
				(-50)	(-50)	(-50)	(-50)	(-50)	(-50)	(-50)	(-50)	(-50)	(-50)	(-50)	(-50)	(-50)	(-50)	(-50)	(-50)
				(-50)	(-50)	(-50)	(-50)	(-50)	(-50)	(-50)	(-50)	(-50)	(-50)	(-50)	(-50)	(-50)	(-50)	(-50)	(-50)
				(-50)	(-50)	(-50)	(-50)	(-50)	(-50)	(-50)	(-50)	(-50)	(-50)	(-50)	(-50)	(-50)	(-50)	(-50)	(-50)
				(-50)	(-50)	(-50)	(-50)	(-50)	(-50)	(-50)	(-50)	(-50)	(-50)	(-50)	(-50)	(-50)	(-50)	(-50)	(-50)
				(-50)	(-50)	(-50)	(-50)	(-50)	(-50)	(-50)	(-50)	(-50)	(-50)	(-50)	(-50)	(-50)	(-50)	(-50)	(-50)
				(-50)	(-50)	(-50)	(-50)	(-50)	(-50)	(-50)	(-50)	(-50)	(-50)	(-50)	(-50)	(-50)	(-50)	(-50)	(-50)
				(-50)	(-50)	(-50)	(-50)	(-50)	(-50)	(-50)	(-50)	(-50)	(-50)	(-50)	(-50)	(-50)	(-50)	(-50)	(-50)
				(-50)	(-50)	(-50)	(-50)	(-50)	(-50)	(-50)	(-50)	(-50)	(-50)	(-50)	(-50)	(-50)	(-50)	(-50)	(-50)
				(-50)	(-50)	(-50)	(-50)	(-50)	(-50)	(-50)	(-50)	(-50)	(-50)	(-50)	(-50)	(-50)	(-50)	(-50)	(-50)
				(-50)	(-50)	(-50)	(-50)	(-50)	(-50)	(-50)	(-50)	(-50)	(-50)	(-50)	(-50)	(-50)	(-50)	(-50)	(-50)
				(-50)	(-50)	(-50)	(-50)	(-50)	(-50)	(-50)	(-50)	(-50)	(-50)	(-50)	(-50)	(-50)	(-50)	(-50)	(-50)
				(-50)	(-50)	(-50)	(-50)	(-50)	(-50)	(-50)	(-50)	(-50)	(-50)	(-50)	(-50)	(-50)	(-50)	(-50)	(-50)
				(-75) (-75) (-75)>;

			PS_Config_Lmt_PenTipX_FW_Raw_P = <
				570 570 570 570 570 570 570 570 570 570 570 570 570 570 570 570 570 570 570 570 570 570 570 570 570 570 570 570 570 570 570 570
				570 570 570 570 570 570 570 570 570 570 570 570 570 570 570 570 570 570 570 570 570 570 570 570 570 570 570 570 570 570 570 570
				570 570 570 570 570 570 570 570 570 570 570 570 570 570 570 570 570 570 570 570 570 570 570 570 570 570 570 570 570 570 570 570
				570 570 570 570 570 570 570 570 570 570 570 570 570 570 570 570 570 570 570 570 570 570 570 570 570 570 570 570 570 570 570 570
				570 570 570 570 570 570 570 570 570 570 570 570 570 570 570 570 570 570 570 570 570 570 570 570 570 570 570 570 570 570 570 570
				570 570 570 570 570 570 570 570 570 570 570 570 570 570 570 570 570 570 570 570 570 570 570 570 570 570 570 570 570 570 570 570>;

			PS_Config_Lmt_PenTipX_FW_Raw_N = <
				(-570) (-570) (-570) (-570) (-570) (-570) (-570) (-570) (-570) (-570) (-570) (-570) (-570) (-570) (-570) (-570) (-570) (-570) (-570) (-570) (-570) (-570) (-570) (-570) (-570) (-570) (-570) (-570) (-570) (-570) (-570) (-570)
				(-570) (-570) (-570) (-570) (-570) (-570) (-570) (-570) (-570) (-570) (-570) (-570) (-570) (-570) (-570) (-570) (-570) (-570) (-570) (-570) (-570) (-570) (-570) (-570) (-570) (-570) (-570) (-570) (-570) (-570) (-570) (-570)
				(-570) (-570) (-570) (-570) (-570) (-570) (-570) (-570) (-570) (-570) (-570) (-570) (-570) (-570) (-570) (-570) (-570) (-570) (-570) (-570) (-570) (-570) (-570) (-570) (-570) (-570) (-570) (-570) (-570) (-570) (-570) (-570)
				(-570) (-570) (-570) (-570) (-570) (-570) (-570) (-570) (-570) (-570) (-570) (-570) (-570) (-570) (-570) (-570) (-570) (-570) (-570) (-570) (-570) (-570) (-570) (-570) (-570) (-570) (-570) (-570) (-570) (-570) (-570) (-570)
				(-570) (-570) (-570) (-570) (-570) (-570) (-570) (-570) (-570) (-570) (-570) (-570) (-570) (-570) (-570) (-570) (-570) (-570) (-570) (-570) (-570) (-570) (-570) (-570) (-570) (-570) (-570) (-570) (-570) (-570) (-570) (-570)
				(-570) (-570) (-570) (-570) (-570) (-570) (-570) (-570) (-570) (-570) (-570) (-570) (-570) (-570) (-570) (-570) (-570) (-570) (-570) (-570) (-570) (-570) (-570) (-570) (-570) (-570) (-570) (-570) (-570) (-570) (-570) (-570)>;

			PS_Config_Lmt_PenTipY_FW_Raw_P = <
				570 570 570 570
				570 570 570 570
				570 570 570 570
				570 570 570 570
				570 570 570 570
				570 570 570 570
				570 570 570 570
				570 570 570 570
				570 570 570 570
				570 570 570 570
				570 570 570 570
				570 570 570 570
				570 570 570 570
				570 570 570 570
				570 570 570 570
				570 570 570 570
				570 570 570 570
				570 570 570 570
				570 570 570 570
				570 570 570 570
				570 570 570 570
				570 570 570 570
				570 570 570 570
				570 570 570 570
				570 570 570 570
				570 570 570 570
				570 570 570 570
				570 570 570 570
				570 570 570 570
				570 570 570 570
				570 570 570 570
				570 570 570 570
				570 570 570 570
				570 570 570 570
				570 570 570 570
				570 570 570 570
				570 570 570 570
				570 570 570 570
				570 570 570 570
				570 570 570 570
				570 570 570 570
				570 570 570 570
				570 570 570 570
				570 570 570 570
				570 570 570 570
				570 570 570 570
				570 570 570 570
				570 570 570 570
				570 570 570 570
				570 570 570 570>;

			PS_Config_Lmt_PenTipY_FW_Raw_N = <
				(-570) (-570) (-570) (-570)
				(-570) (-570) (-570) (-570)
				(-570) (-570) (-570) (-570)
				(-570) (-570) (-570) (-570)
				(-570) (-570) (-570) (-570)
				(-570) (-570) (-570) (-570)
				(-570) (-570) (-570) (-570)
				(-570) (-570) (-570) (-570)
				(-570) (-570) (-570) (-570)
				(-570) (-570) (-570) (-570)
				(-570) (-570) (-570) (-570)
				(-570) (-570) (-570) (-570)
				(-570) (-570) (-570) (-570)
				(-570) (-570) (-570) (-570)
				(-570) (-570) (-570) (-570)
				(-570) (-570) (-570) (-570)
				(-570) (-570) (-570) (-570)
				(-570) (-570) (-570) (-570)
				(-570) (-570) (-570) (-570)
				(-570) (-570) (-570) (-570)
				(-570) (-570) (-570) (-570)
				(-570) (-570) (-570) (-570)
				(-570) (-570) (-570) (-570)
				(-570) (-570) (-570) (-570)
				(-570) (-570) (-570) (-570)
				(-570) (-570) (-570) (-570)
				(-570) (-570) (-570) (-570)
				(-570) (-570) (-570) (-570)
				(-570) (-570) (-570) (-570)
				(-570) (-570) (-570) (-570)
				(-570) (-570) (-570) (-570)
				(-570) (-570) (-570) (-570)
				(-570) (-570) (-570) (-570)
				(-570) (-570) (-570) (-570)
				(-570) (-570) (-570) (-570)
				(-570) (-570) (-570) (-570)
				(-570) (-570) (-570) (-570)
				(-570) (-570) (-570) (-570)
				(-570) (-570) (-570) (-570)
				(-570) (-570) (-570) (-570)
				(-570) (-570) (-570) (-570)
				(-570) (-570) (-570) (-570)
				(-570) (-570) (-570) (-570)
				(-570) (-570) (-570) (-570)
				(-570) (-570) (-570) (-570)
				(-570) (-570) (-570) (-570)
				(-570) (-570) (-570) (-570)
				(-570) (-570) (-570) (-570)
				(-570) (-570) (-570) (-570)
				(-570) (-570) (-570) (-570)>;

			PS_Config_Lmt_PenRingX_FW_Raw_P = <
				570 570 570 570 570 570 570 570 570 570 570 570 570 570 570 570 570 570 570 570 570 570 570 570 570 570 570 570 570 570 570 570
				570 570 570 570 570 570 570 570 570 570 570 570 570 570 570 570 570 570 570 570 570 570 570 570 570 570 570 570 570 570 570 570
				570 570 570 570 570 570 570 570 570 570 570 570 570 570 570 570 570 570 570 570 570 570 570 570 570 570 570 570 570 570 570 570
				570 570 570 570 570 570 570 570 570 570 570 570 570 570 570 570 570 570 570 570 570 570 570 570 570 570 570 570 570 570 570 570
				570 570 570 570 570 570 570 570 570 570 570 570 570 570 570 570 570 570 570 570 570 570 570 570 570 570 570 570 570 570 570 570
				570 570 570 570 570 570 570 570 570 570 570 570 570 570 570 570 570 570 570 570 570 570 570 570 570 570 570 570 570 570 570 570>;

			PS_Config_Lmt_PenRingX_FW_Raw_N = <
				(-570) (-570) (-570) (-570) (-570) (-570) (-570) (-570) (-570) (-570) (-570) (-570) (-570) (-570) (-570) (-570) (-570) (-570) (-570) (-570) (-570) (-570) (-570) (-570) (-570) (-570) (-570) (-570) (-570) (-570) (-570) (-570)
				(-570) (-570) (-570) (-570) (-570) (-570) (-570) (-570) (-570) (-570) (-570) (-570) (-570) (-570) (-570) (-570) (-570) (-570) (-570) (-570) (-570) (-570) (-570) (-570) (-570) (-570) (-570) (-570) (-570) (-570) (-570) (-570)
				(-570) (-570) (-570) (-570) (-570) (-570) (-570) (-570) (-570) (-570) (-570) (-570) (-570) (-570) (-570) (-570) (-570) (-570) (-570) (-570) (-570) (-570) (-570) (-570) (-570) (-570) (-570) (-570) (-570) (-570) (-570) (-570)
				(-570) (-570) (-570) (-570) (-570) (-570) (-570) (-570) (-570) (-570) (-570) (-570) (-570) (-570) (-570) (-570) (-570) (-570) (-570) (-570) (-570) (-570) (-570) (-570) (-570) (-570) (-570) (-570) (-570) (-570) (-570) (-570)
				(-570) (-570) (-570) (-570) (-570) (-570) (-570) (-570) (-570) (-570) (-570) (-570) (-570) (-570) (-570) (-570) (-570) (-570) (-570) (-570) (-570) (-570) (-570) (-570) (-570) (-570) (-570) (-570) (-570) (-570) (-570) (-570)
				(-570) (-570) (-570) (-570) (-570) (-570) (-570) (-570) (-570) (-570) (-570) (-570) (-570) (-570) (-570) (-570) (-570) (-570) (-570) (-570) (-570) (-570) (-570) (-570) (-570) (-570) (-570) (-570) (-570) (-570) (-570) (-570)>;

			PS_Config_Lmt_PenRingY_FW_Raw_P = <
				570 570 570 570
				570 570 570 570
				570 570 570 570
				570 570 570 570
				570 570 570 570
				570 570 570 570
				570 570 570 570
				570 570 570 570
				570 570 570 570
				570 570 570 570
				570 570 570 570
				570 570 570 570
				570 570 570 570
				570 570 570 570
				570 570 570 570
				570 570 570 570
				570 570 570 570
				570 570 570 570
				570 570 570 570
				570 570 570 570
				570 570 570 570
				570 570 570 570
				570 570 570 570
				570 570 570 570
				570 570 570 570
				570 570 570 570
				570 570 570 570
				570 570 570 570
				570 570 570 570
				570 570 570 570
				570 570 570 570
				570 570 570 570
				570 570 570 570
				570 570 570 570
				570 570 570 570
				570 570 570 570
				570 570 570 570
				570 570 570 570
				570 570 570 570
				570 570 570 570
				570 570 570 570
				570 570 570 570
				570 570 570 570
				570 570 570 570
				570 570 570 570
				570 570 570 570
				570 570 570 570
				570 570 570 570
				570 570 570 570
				570 570 570 570>;

			PS_Config_Lmt_PenRingY_FW_Raw_N = <
				(-570) (-570) (-570) (-570)
				(-570) (-570) (-570) (-570)
				(-570) (-570) (-570) (-570)
				(-570) (-570) (-570) (-570)
				(-570) (-570) (-570) (-570)
				(-570) (-570) (-570) (-570)
				(-570) (-570) (-570) (-570)
				(-570) (-570) (-570) (-570)
				(-570) (-570) (-570) (-570)
				(-570) (-570) (-570) (-570)
				(-570) (-570) (-570) (-570)
				(-570) (-570) (-570) (-570)
				(-570) (-570) (-570) (-570)
				(-570) (-570) (-570) (-570)
				(-570) (-570) (-570) (-570)
				(-570) (-570) (-570) (-570)
				(-570) (-570) (-570) (-570)
				(-570) (-570) (-570) (-570)
				(-570) (-570) (-570) (-570)
				(-570) (-570) (-570) (-570)
				(-570) (-570) (-570) (-570)
				(-570) (-570) (-570) (-570)
				(-570) (-570) (-570) (-570)
				(-570) (-570) (-570) (-570)
				(-570) (-570) (-570) (-570)
				(-570) (-570) (-570) (-570)
				(-570) (-570) (-570) (-570)
				(-570) (-570) (-570) (-570)
				(-570) (-570) (-570) (-570)
				(-570) (-570) (-570) (-570)
				(-570) (-570) (-570) (-570)
				(-570) (-570) (-570) (-570)
				(-570) (-570) (-570) (-570)
				(-570) (-570) (-570) (-570)
				(-570) (-570) (-570) (-570)
				(-570) (-570) (-570) (-570)
				(-570) (-570) (-570) (-570)
				(-570) (-570) (-570) (-570)
				(-570) (-570) (-570) (-570)
				(-570) (-570) (-570) (-570)
				(-570) (-570) (-570) (-570)
				(-570) (-570) (-570) (-570)
				(-570) (-570) (-570) (-570)
				(-570) (-570) (-570) (-570)
				(-570) (-570) (-570) (-570)
				(-570) (-570) (-570) (-570)
				(-570) (-570) (-570) (-570)
				(-570) (-570) (-570) (-570)
				(-570) (-570) (-570) (-570)
				(-570) (-570) (-570) (-570)>;

			PS_Config_Lmt_PenTipX_FW_Diff_P = <
				870 870 870 870 870 870 870 870 870 870 870 870 870 870 870 870 870 870 870 870 870 870 870 870 870 870 870 870 870 870 870 870
				870 870 870 870 870 870 870 870 870 870 870 870 870 870 870 870 870 870 870 870 870 870 870 870 870 870 870 870 870 870 870 870
				870 870 870 870 870 870 870 870 870 870 870 870 870 870 870 870 870 870 870 870 870 870 870 870 870 870 870 870 870 870 870 870
				870 870 870 870 870 870 870 870 870 870 870 870 870 870 870 870 870 870 870 870 870 870 870 870 870 870 870 870 870 870 870 870
				870 870 870 870 870 870 870 870 870 870 870 870 870 870 870 870 870 870 870 870 870 870 870 870 870 870 870 870 870 870 870 870
				870 870 870 870 870 870 870 870 870 870 870 870 870 870 870 870 870 870 870 870 870 870 870 870 870 870 870 870 870 870 870 870>;

			PS_Config_Lmt_PenTipX_FW_Diff_N = <
				(-870) (-870) (-870) (-870) (-870) (-870) (-870) (-870) (-870) (-870) (-870) (-870) (-870) (-870) (-870) (-870) (-870) (-870) (-870) (-870) (-870) (-870) (-870) (-870) (-870) (-870) (-870) (-870) (-870) (-870) (-870) (-870)
				(-870) (-870) (-870) (-870) (-870) (-870) (-870) (-870) (-870) (-870) (-870) (-870) (-870) (-870) (-870) (-870) (-870) (-870) (-870) (-870) (-870) (-870) (-870) (-870) (-870) (-870) (-870) (-870) (-870) (-870) (-870) (-870)
				(-870) (-870) (-870) (-870) (-870) (-870) (-870) (-870) (-870) (-870) (-870) (-870) (-870) (-870) (-870) (-870) (-870) (-870) (-870) (-870) (-870) (-870) (-870) (-870) (-870) (-870) (-870) (-870) (-870) (-870) (-870) (-870)
				(-870) (-870) (-870) (-870) (-870) (-870) (-870) (-870) (-870) (-870) (-870) (-870) (-870) (-870) (-870) (-870) (-870) (-870) (-870) (-870) (-870) (-870) (-870) (-870) (-870) (-870) (-870) (-870) (-870) (-870) (-870) (-870)
				(-870) (-870) (-870) (-870) (-870) (-870) (-870) (-870) (-870) (-870) (-870) (-870) (-870) (-870) (-870) (-870) (-870) (-870) (-870) (-870) (-870) (-870) (-870) (-870) (-870) (-870) (-870) (-870) (-870) (-870) (-870) (-870)
				(-870) (-870) (-870) (-870) (-870) (-870) (-870) (-870) (-870) (-870) (-870) (-870) (-870) (-870) (-870) (-870) (-870) (-870) (-870) (-870) (-870) (-870) (-870) (-870) (-870) (-870) (-870) (-870) (-870) (-870) (-870) (-870)>;

			PS_Config_Lmt_PenTipY_FW_Diff_P = <
				870 870 870 870
				870 870 870 870
				870 870 870 870
				870 870 870 870
				870 870 870 870
				870 870 870 870
				870 870 870 870
				870 870 870 870
				870 870 870 870
				870 870 870 870
				870 870 870 870
				870 870 870 870
				870 870 870 870
				870 870 870 870
				870 870 870 870
				870 870 870 870
				870 870 870 870
				870 870 870 870
				870 870 870 870
				870 870 870 870
				870 870 870 870
				870 870 870 870
				870 870 870 870
				870 870 870 870
				870 870 870 870
				870 870 870 870
				870 870 870 870
				870 870 870 870
				870 870 870 870
				870 870 870 870
				870 870 870 870
				870 870 870 870
				870 870 870 870
				870 870 870 870
				870 870 870 870
				870 870 870 870
				870 870 870 870
				870 870 870 870
				870 870 870 870
				870 870 870 870
				870 870 870 870
				870 870 870 870
				870 870 870 870
				870 870 870 870
				870 870 870 870
				870 870 870 870
				870 870 870 870
				870 870 870 870
				870 870 870 870
				870 870 870 870>;

			PS_Config_Lmt_PenTipY_FW_Diff_N = <
				(-870) (-870) (-870) (-870)
				(-870) (-870) (-870) (-870)
				(-870) (-870) (-870) (-870)
				(-870) (-870) (-870) (-870)
				(-870) (-870) (-870) (-870)
				(-870) (-870) (-870) (-870)
				(-870) (-870) (-870) (-870)
				(-870) (-870) (-870) (-870)
				(-870) (-870) (-870) (-870)
				(-870) (-870) (-870) (-870)
				(-870) (-870) (-870) (-870)
				(-870) (-870) (-870) (-870)
				(-870) (-870) (-870) (-870)
				(-870) (-870) (-870) (-870)
				(-870) (-870) (-870) (-870)
				(-870) (-870) (-870) (-870)
				(-870) (-870) (-870) (-870)
				(-870) (-870) (-870) (-870)
				(-870) (-870) (-870) (-870)
				(-870) (-870) (-870) (-870)
				(-870) (-870) (-870) (-870)
				(-870) (-870) (-870) (-870)
				(-870) (-870) (-870) (-870)
				(-870) (-870) (-870) (-870)
				(-870) (-870) (-870) (-870)
				(-870) (-870) (-870) (-870)
				(-870) (-870) (-870) (-870)
				(-870) (-870) (-870) (-870)
				(-870) (-870) (-870) (-870)
				(-870) (-870) (-870) (-870)
				(-870) (-870) (-870) (-870)
				(-870) (-870) (-870) (-870)
				(-870) (-870) (-870) (-870)
				(-870) (-870) (-870) (-870)
				(-870) (-870) (-870) (-870)
				(-870) (-870) (-870) (-870)
				(-870) (-870) (-870) (-870)
				(-870) (-870) (-870) (-870)
				(-870) (-870) (-870) (-870)
				(-870) (-870) (-870) (-870)
				(-870) (-870) (-870) (-870)
				(-870) (-870) (-870) (-870)
				(-870) (-870) (-870) (-870)
				(-870) (-870) (-870) (-870)
				(-870) (-870) (-870) (-870)
				(-870) (-870) (-870) (-870)
				(-870) (-870) (-870) (-870)
				(-870) (-870) (-870) (-870)
				(-870) (-870) (-870) (-870)
				(-870) (-870) (-870) (-870)>;

			PS_Config_Lmt_PenRingX_FW_Diff_P = <
				870 870 870 870 870 870 870 870 870 870 870 870 870 870 870 870 870 870 870 870 870 870 870 870 870 870 870 870 870 870 870 870
				870 870 870 870 870 870 870 870 870 870 870 870 870 870 870 870 870 870 870 870 870 870 870 870 870 870 870 870 870 870 870 870
				870 870 870 870 870 870 870 870 870 870 870 870 870 870 870 870 870 870 870 870 870 870 870 870 870 870 870 870 870 870 870 870
				870 870 870 870 870 870 870 870 870 870 870 870 870 870 870 870 870 870 870 870 870 870 870 870 870 870 870 870 870 870 870 870
				870 870 870 870 870 870 870 870 870 870 870 870 870 870 870 870 870 870 870 870 870 870 870 870 870 870 870 870 870 870 870 870
				870 870 870 870 870 870 870 870 870 870 870 870 870 870 870 870 870 870 870 870 870 870 870 870 870 870 870 870 870 870 870 870>;

			PS_Config_Lmt_PenRingX_FW_Diff_N = <
				(-870) (-870) (-870) (-870) (-870) (-870) (-870) (-870) (-870) (-870) (-870) (-870) (-870) (-870) (-870) (-870) (-870) (-870) (-870) (-870) (-870) (-870) (-870) (-870) (-870) (-870) (-870) (-870) (-870) (-870) (-870) (-870)
				(-870) (-870) (-870) (-870) (-870) (-870) (-870) (-870) (-870) (-870) (-870) (-870) (-870) (-870) (-870) (-870) (-870) (-870) (-870) (-870) (-870) (-870) (-870) (-870) (-870) (-870) (-870) (-870) (-870) (-870) (-870) (-870)
				(-870) (-870) (-870) (-870) (-870) (-870) (-870) (-870) (-870) (-870) (-870) (-870) (-870) (-870) (-870) (-870) (-870) (-870) (-870) (-870) (-870) (-870) (-870) (-870) (-870) (-870) (-870) (-870) (-870) (-870) (-870) (-870)
				(-870) (-870) (-870) (-870) (-870) (-870) (-870) (-870) (-870) (-870) (-870) (-870) (-870) (-870) (-870) (-870) (-870) (-870) (-870) (-870) (-870) (-870) (-870) (-870) (-870) (-870) (-870) (-870) (-870) (-870) (-870) (-870)
				(-870) (-870) (-870) (-870) (-870) (-870) (-870) (-870) (-870) (-870) (-870) (-870) (-870) (-870) (-870) (-870) (-870) (-870) (-870) (-870) (-870) (-870) (-870) (-870) (-870) (-870) (-870) (-870) (-870) (-870) (-870) (-870)
				(-870) (-870) (-870) (-870) (-870) (-870) (-870) (-870) (-870) (-870) (-870) (-870) (-870) (-870) (-870) (-870) (-870) (-870) (-870) (-870) (-870) (-870) (-870) (-870) (-870) (-870) (-870) (-870) (-870) (-870) (-870) (-870)>;

			PS_Config_Lmt_PenRingY_FW_Diff_P = <
				870 870 870 870
				870 870 870 870
				870 870 870 870
				870 870 870 870
				870 870 870 870
				870 870 870 870
				870 870 870 870
				870 870 870 870
				870 870 870 870
				870 870 870 870
				870 870 870 870
				870 870 870 870
				870 870 870 870
				870 870 870 870
				870 870 870 870
				870 870 870 870
				870 870 870 870
				870 870 870 870
				870 870 870 870
				870 870 870 870
				870 870 870 870
				870 870 870 870
				870 870 870 870
				870 870 870 870
				870 870 870 870
				870 870 870 870
				870 870 870 870
				870 870 870 870
				870 870 870 870
				870 870 870 870
				870 870 870 870
				870 870 870 870
				870 870 870 870
				870 870 870 870
				870 870 870 870
				870 870 870 870
				870 870 870 870
				870 870 870 870
				870 870 870 870
				870 870 870 870
				870 870 870 870
				870 870 870 870
				870 870 870 870
				870 870 870 870
				870 870 870 870
				870 870 870 870
				870 870 870 870
				870 870 870 870
				870 870 870 870
				870 870 870 870>;

			PS_Config_Lmt_PenRingY_FW_Diff_N = <
				(-870) (-870) (-870) (-870)
				(-870) (-870) (-870) (-870)
				(-870) (-870) (-870) (-870)
				(-870) (-870) (-870) (-870)
				(-870) (-870) (-870) (-870)
				(-870) (-870) (-870) (-870)
				(-870) (-870) (-870) (-870)
				(-870) (-870) (-870) (-870)
				(-870) (-870) (-870) (-870)
				(-870) (-870) (-870) (-870)
				(-870) (-870) (-870) (-870)
				(-870) (-870) (-870) (-870)
				(-870) (-870) (-870) (-870)
				(-870) (-870) (-870) (-870)
				(-870) (-870) (-870) (-870)
				(-870) (-870) (-870) (-870)
				(-870) (-870) (-870) (-870)
				(-870) (-870) (-870) (-870)
				(-870) (-870) (-870) (-870)
				(-870) (-870) (-870) (-870)
				(-870) (-870) (-870) (-870)
				(-870) (-870) (-870) (-870)
				(-870) (-870) (-870) (-870)
				(-870) (-870) (-870) (-870)
				(-870) (-870) (-870) (-870)
				(-870) (-870) (-870) (-870)
				(-870) (-870) (-870) (-870)
				(-870) (-870) (-870) (-870)
				(-870) (-870) (-870) (-870)
				(-870) (-870) (-870) (-870)
				(-870) (-870) (-870) (-870)
				(-870) (-870) (-870) (-870)
				(-870) (-870) (-870) (-870)
				(-870) (-870) (-870) (-870)
				(-870) (-870) (-870) (-870)
				(-870) (-870) (-870) (-870)
				(-870) (-870) (-870) (-870)
				(-870) (-870) (-870) (-870)
				(-870) (-870) (-870) (-870)
				(-870) (-870) (-870) (-870)
				(-870) (-870) (-870) (-870)
				(-870) (-870) (-870) (-870)
				(-870) (-870) (-870) (-870)
				(-870) (-870) (-870) (-870)
				(-870) (-870) (-870) (-870)
				(-870) (-870) (-870) (-870)
				(-870) (-870) (-870) (-870)
				(-870) (-870) (-870) (-870)
				(-870) (-870) (-870) (-870)
				(-870) (-870) (-870) (-870)>;

			PS_Config_Diff_Test_Frame = <50>;
		};
	};
};

/* Huaqin modify for HQ-123586 by shujiawang at 2021/04/16 end */

/* TOUCH end */
